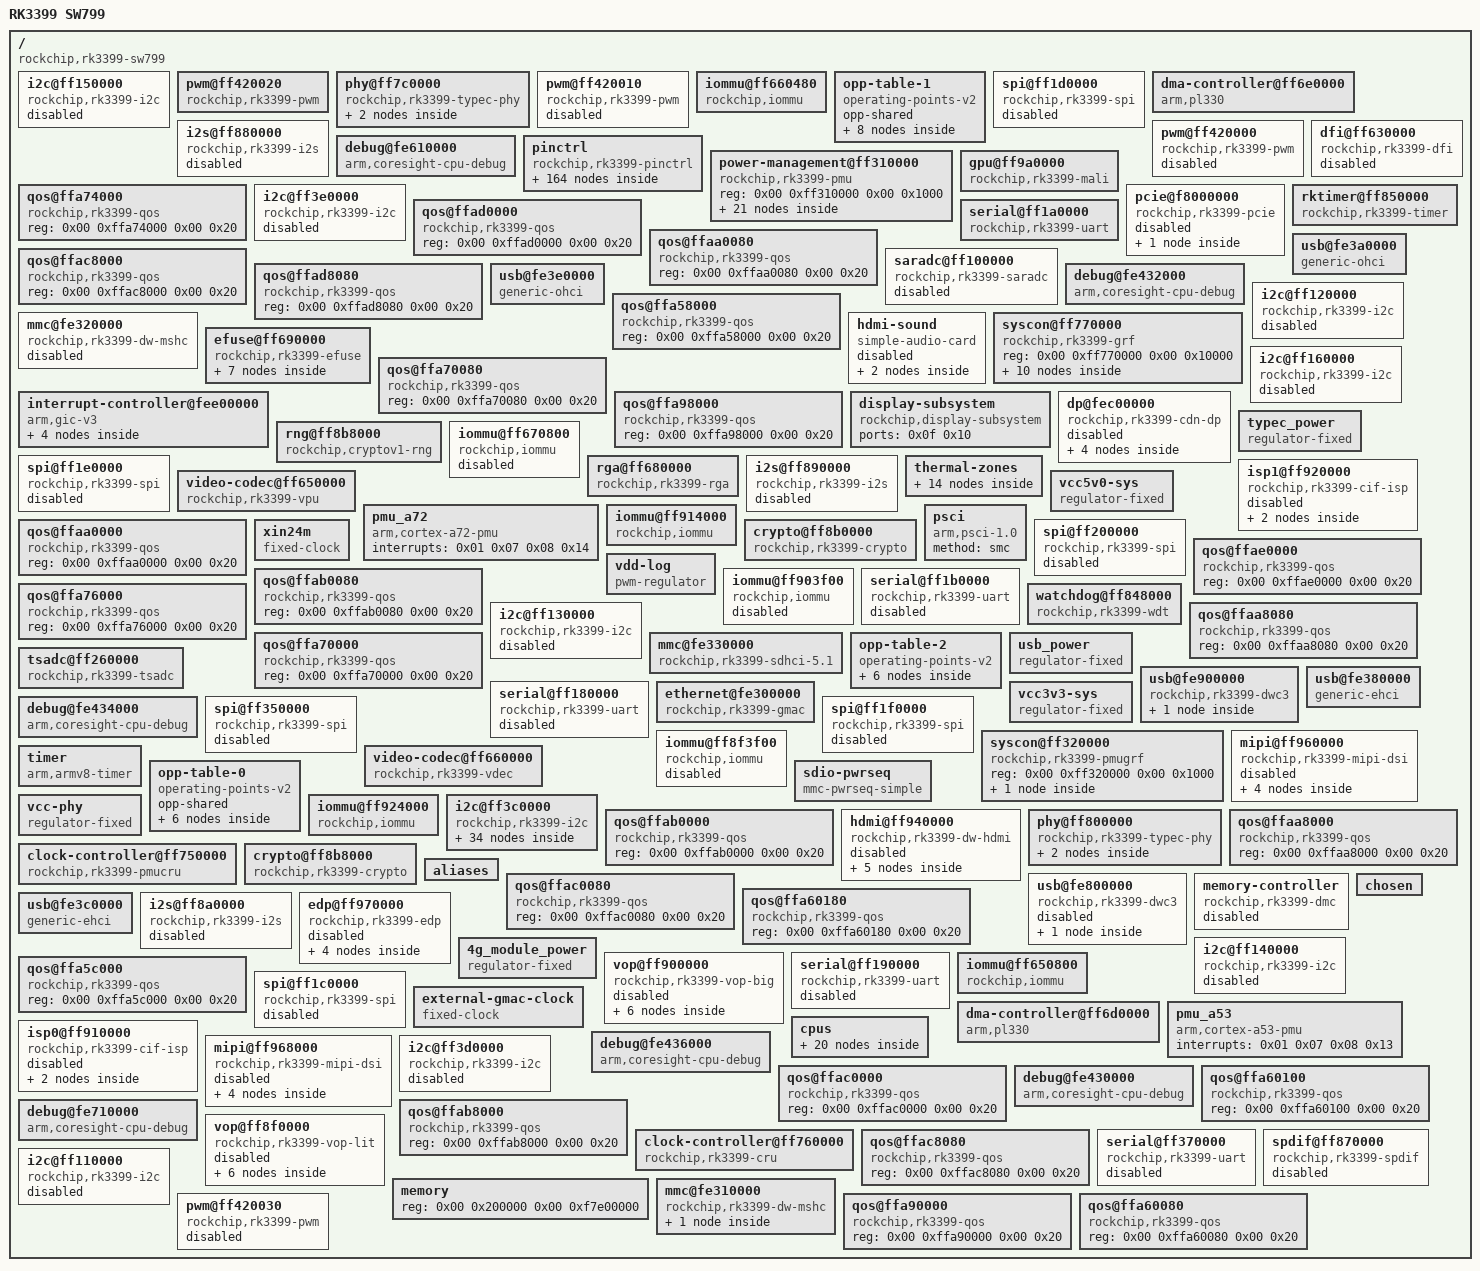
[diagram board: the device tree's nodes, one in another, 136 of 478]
/dts-v1/;

/ {
	#address-cells = <0x02>;
	model = "RK3399 SW799";
	serial-number = "8e98f8455ed5334b";
	#size-cells = <0x02>;
	interrupt-parent = <0x01>;
	compatible = "rockchip,rk3399-sw799", "rockchip,rk3399";

	i2c@ff150000 {
		pinctrl-names = "default";
		#address-cells = <0x01>;
		pinctrl-0 = <0x34>;
		clock-names = "i2c", "pclk";
		assigned-clocks = <0x08 0x45>;
		assigned-clock-rates = <0xbebc200>;
		interrupts = <0x00 0x25 0x04 0x00>;
		clocks = <0x08 0x45 0x08 0x159>;
		#size-cells = <0x00>;
		compatible = "rockchip,rk3399-i2c";
		status = "disabled";
		reg = <0x00 0xff150000 0x00 0x1000>;
		phandle = <0xc0>;
	};

	pwm@ff420020 {
		pinctrl-names = "default";
		pinctrl-0 = <0x7b>;
		clocks = <0x6c 0x1e>;
		#pwm-cells = <0x03>;
		compatible = "rockchip,rk3399-pwm", "rockchip,rk3288-pwm";
		status = "okay";
		reg = <0x00 0xff420020 0x00 0x10>;
		phandle = <0xa7>;
	};

	phy@ff7c0000 {
		power-domains = <0x18 0x08>;
		clock-names = "tcpdcore", "tcpdphy-ref";
		assigned-clocks = <0x08 0x7e>;
		assigned-clock-rates = <0x2faf080>;
		resets = <0x08 0x95 0x08 0x94 0x08 0x14c>;
		clocks = <0x08 0x7e 0x08 0x7d>;
		compatible = "rockchip,rk3399-typec-phy";
		status = "okay";
		rockchip,grf = <0x19>;
		reg = <0x00 0xff7c0000 0x00 0x40000>;
		phandle = <0xf7>;
		reset-names = "uphy", "uphy-pipe", "uphy-tcphy";

		dp-port {
			#phy-cells = <0x00>;
			phandle = <0x2c>;
		};

		usb3-port {
			#phy-cells = <0x00>;
			phandle = <0x29>;
		};
	};

	pwm@ff420010 {
		pinctrl-names = "default";
		pinctrl-0 = <0x7a>;
		clocks = <0x6c 0x1e>;
		#pwm-cells = <0x03>;
		compatible = "rockchip,rk3399-pwm", "rockchip,rk3288-pwm";
		status = "disabled";
		reg = <0x00 0xff420010 0x00 0x10>;
		phandle = <0xe8>;
	};

	iommu@ff660480 {
		power-domains = <0x18 0x20>;
		clock-names = "aclk", "iface";
		interrupts = <0x00 0x75 0x04 0x00>;
		clocks = <0x08 0xed 0x08 0x1ec>;
		#iommu-cells = <0x00>;
		compatible = "rockchip,iommu";
		reg = <0x00 0xff660480 0x00 0x40 0x00 0xff6604c0 0x00 0x40>;
		phandle = <0x7e>;
	};

	opp-table-1 {
		opp-shared;
		compatible = "operating-points-v2";
		phandle = <0x0d>;

		opp04 {
			opp-microvolt = <0xe7ef0 0xe7ef0 0x1312d0>;
			opp-hz = <0x00 0x47868c00>;
		};

		opp02 {
			opp-microvolt = <0xc96a8 0xc96a8 0x1312d0>;
			opp-hz = <0x00 0x30a32c00>;
		};

		opp00 {
			opp-microvolt = <0xc96a8 0xc96a8 0x1312d0>;
			opp-hz = <0x00 0x18519600>;
			clock-latency-ns = <0x9c40>;
		};

		opp07 {
			opp-microvolt = <0x124f80 0x124f80 0x1312d0>;
			opp-hz = <0x00 0x6b49d200>;
		};

		opp05 {
			opp-microvolt = <0xfa3e8 0xfa3e8 0x1312d0>;
			opp-hz = <0x00 0x54667200>;
		};

		opp03 {
			opp-microvolt = <0xd59f8 0xd59f8 0x1312d0>;
			opp-hz = <0x00 0x3c14dc00>;
		};

		opp01 {
			opp-microvolt = <0xc96a8 0xc96a8 0x1312d0>;
			opp-hz = <0x00 0x23c34600>;
		};

		opp06 {
			opp-microvolt = <0x10c8e0 0x10c8e0 0x1312d0>;
			opp-hz = <0x00 0x5fd82200>;
		};
	};

	spi@ff1d0000 {
		pinctrl-names = "default";
		#address-cells = <0x01>;
		pinctrl-0 = <0x3f 0x40 0x41 0x42>;
		clock-names = "spiclk", "apb_pclk";
		interrupts = <0x00 0x35 0x04 0x00>;
		clocks = <0x08 0x48 0x08 0x15c>;
		#size-cells = <0x00>;
		dma-names = "tx", "rx";
		compatible = "rockchip,rk3399-spi", "rockchip,rk3066-spi";
		status = "disabled";
		reg = <0x00 0xff1d0000 0x00 0x1000>;
		phandle = <0xc7>;
		dmas = <0x3a 0x0c 0x3a 0x0d>;
	};

	dma-controller@ff6e0000 {
		clock-names = "apb_pclk";
		interrupts = <0x00 0x07 0x04 0x00 0x00 0x08 0x04 0x00>;
		clocks = <0x08 0xd4>;
		arm,pl330-periph-burst;
		compatible = "arm,pl330", "arm,primecell";
		reg = <0x00 0xff6e0000 0x00 0x4000>;
		phandle = <0x3a>;
		#dma-cells = <0x01>;
	};

	i2s@ff880000 {
		power-domains = <0x18 0x1c>;
		pinctrl-names = "bclk_on", "bclk_off";
		pinctrl-0 = <0x82>;
		clock-names = "i2s_clk", "i2s_hclk";
		interrupts = <0x00 0x27 0x04 0x00>;
		clocks = <0x08 0x56 0x08 0x1d4>;
		dma-names = "tx", "rx";
		#sound-dai-cells = <0x00>;
		compatible = "rockchip,rk3399-i2s", "rockchip,rk3066-i2s";
		pinctrl-1 = <0x83>;
		status = "disabled";
		rockchip,grf = <0x19>;
		reg = <0x00 0xff880000 0x00 0x1000>;
		phandle = <0xfb>;
		dmas = <0x4b 0x00 0x4b 0x01>;
	};

	pwm@ff420000 {
		pinctrl-names = "default";
		pinctrl-0 = <0x79>;
		clocks = <0x6c 0x1e>;
		#pwm-cells = <0x03>;
		compatible = "rockchip,rk3399-pwm", "rockchip,rk3288-pwm";
		status = "disabled";
		reg = <0x00 0xff420000 0x00 0x10>;
		phandle = <0xe7>;
	};

	debug@fe610000 {
		clock-names = "apb_pclk";
		clocks = <0x08 0x14c>;
		cpu = <0x06>;
		compatible = "arm,coresight-cpu-debug", "arm,primecell";
		reg = <0x00 0xfe610000 0x00 0x1000>;
	};

	pinctrl {
		#address-cells = <0x02>;
		#size-cells = <0x02>;
		compatible = "rockchip,rk3399-pinctrl";
		rockchip,pmu = <0x11>;
		ranges;
		rockchip,grf = <0x19>;
		phandle = <0x10a>;

		i2c3 {

			i2c3-xfer {
				rockchip,pins = <0x04 0x11 0x01 0xa2 0x04 0x10 0x01 0xa2>;
				phandle = <0x32>;
			};
		};

		clock {

			clk-32k {
				rockchip,pins = <0x00 0x00 0x02 0xa2>;
				phandle = <0x11c>;
			};
		};

		spi2 {

			spi2-clk {
				rockchip,pins = <0x02 0x0b 0x01 0xa5>;
				phandle = <0x43>;
			};

			spi2-cs0 {
				rockchip,pins = <0x02 0x0c 0x01 0xa5>;
				phandle = <0x46>;
			};

			spi2-tx {
				rockchip,pins = <0x02 0x0a 0x01 0xa5>;
				phandle = <0x44>;
			};

			spi2-rx {
				rockchip,pins = <0x02 0x09 0x01 0xa5>;
				phandle = <0x45>;
			};
		};

		pcfg-pull-none-12ma {
			drive-strength = <0x0c>;
			bias-disable;
			phandle = <0xa4>;
		};

		pcfg-pull-up-20ma {
			drive-strength = <0x14>;
			phandle = <0x111>;
			bias-pull-up;
		};

		gpio@ff720000 {
			gpio-controller;
			interrupts = <0x00 0x0e 0x04 0x00>;
			clocks = <0x6c 0x17>;
			compatible = "rockchip,gpio-bank";
			#interrupt-cells = <0x02>;
			reg = <0x00 0xff720000 0x00 0x100>;
			phandle = <0x22>;
			#gpio-cells = <0x02>;
			interrupt-controller;
		};

		pcfg-input-pull-up {
			phandle = <0x11a>;
			bias-pull-up;
			input-enable;
		};

		i2s1 {

			i2s1-2ch-bus-bclk-off {
				rockchip,pins = <0x04 0x03 0x00 0xa2 0x04 0x04 0x01 0xa2 0x04 0x05 0x01 0xa2 0x04 0x06 0x01 0xa2 0x04 0x07 0x01 0xa2>;
				phandle = <0x122>;
			};

			i2s1-2ch-bus {
				rockchip,pins = <0x04 0x03 0x01 0xa2 0x04 0x04 0x01 0xa2 0x04 0x05 0x01 0xa2 0x04 0x06 0x01 0xa2 0x04 0x07 0x01 0xa2>;
				phandle = <0x84>;
			};
		};

		i2c1 {

			i2c1-xfer {
				rockchip,pins = <0x04 0x02 0x01 0xa2 0x04 0x01 0x01 0xa2>;
				phandle = <0x30>;
			};
		};

		gmac {

			rmii-pins {
				rockchip,pins = <0x03 0x0d 0x01 0xa2 0x03 0x0c 0x01 0xa3 0x03 0x0b 0x01 0xa2 0x03 0x0a 0x01 0xa2 0x03 0x09 0x01 0xa2 0x03 0x08 0x01 0xa2 0x03 0x07 0x01 0xa2 0x03 0x06 0x01 0xa2 0x03 0x05 0x01 0xa3 0x03 0x04 0x01 0xa3>;
				phandle = <0x11f>;
			};

			rgmii-pins {
				rockchip,pins = <0x03 0x11 0x01 0xa3 0x03 0x0e 0x01 0xa2 0x03 0x0d 0x01 0xa2 0x03 0x0c 0x01 0xa3 0x03 0x0b 0x01 0xa2 0x03 0x09 0x01 0xa2 0x03 0x08 0x01 0xa2 0x03 0x07 0x01 0xa2 0x03 0x06 0x01 0xa2 0x03 0x05 0x01 0xa3 0x03 0x04 0x01 0xa3 0x03 0x03 0x01 0xa2 0x03 0x02 0x01 0xa2 0x03 0x01 0x01 0xa3 0x03 0x00 0x01 0xa3>;
				phandle = <0x1d>;
			};
		};

		spi0 {

			spi0-tx {
				rockchip,pins = <0x03 0x05 0x02 0xa5>;
				phandle = <0x3c>;
			};

			spi0-rx {
				rockchip,pins = <0x03 0x04 0x02 0xa5>;
				phandle = <0x3d>;
			};

			spi0-cs1 {
				rockchip,pins = <0x03 0x08 0x02 0xa5>;
				phandle = <0x132>;
			};

			spi0-clk {
				rockchip,pins = <0x03 0x06 0x02 0xa5>;
				phandle = <0x3b>;
			};

			spi0-cs0 {
				rockchip,pins = <0x03 0x07 0x02 0xa5>;
				phandle = <0x3e>;
			};
		};

		pcfg-pull-down-4ma {
			drive-strength = <0x04>;
			bias-pull-down;
			phandle = <0x112>;
		};

		pcfg-pull-down {
			bias-pull-down;
			phandle = <0xa6>;
		};

		uart4 {

			uart4-xfer {
				rockchip,pins = <0x01 0x07 0x01 0xa5 0x01 0x08 0x01 0xa2>;
				phandle = <0x71>;
			};
		};

		pcfg-pull-none-18ma {
			drive-strength = <0x12>;
			bias-disable;
			phandle = <0x10c>;
		};

		i2c8 {

			i2c8-xfer {
				rockchip,pins = <0x01 0x15 0x01 0xa2 0x01 0x14 0x01 0xa2>;
				phandle = <0x78>;
			};
		};

		pcfg-input-pull-down {
			bias-pull-down;
			phandle = <0x11b>;
			input-enable;
		};

		pcfg-pull-none-20ma {
			drive-strength = <0x14>;
			bias-disable;
			phandle = <0x10d>;
		};

		gpio@ff730000 {
			gpio-controller;
			interrupts = <0x00 0x0f 0x04 0x00>;
			clocks = <0x6c 0x18>;
			compatible = "rockchip,gpio-bank";
			#interrupt-cells = <0x02>;
			reg = <0x00 0xff730000 0x00 0x100>;
			phandle = <0x74>;
			#gpio-cells = <0x02>;
			interrupt-controller;
		};

		i2c6 {

			i2c6-xfer {
				rockchip,pins = <0x02 0x0a 0x02 0xa2 0x02 0x09 0x02 0xa2>;
				phandle = <0x34>;
			};
		};

		uarthdcp {

			uarthdcp-xfer {
				rockchip,pins = <0x04 0x15 0x02 0xa5 0x04 0x16 0x02 0xa2>;
				phandle = <0x13c>;
			};
		};

		pwm1 {

			pwm1-pin {
				rockchip,pins = <0x04 0x16 0x01 0xa2>;
				phandle = <0x7a>;
			};

			pwm1-pin-pull-down {
				rockchip,pins = <0x04 0x16 0x01 0xa6>;
				phandle = <0x140>;
			};
		};

		uart2b {

			uart2b-xfer {
				rockchip,pins = <0x04 0x10 0x02 0xa5 0x04 0x11 0x02 0xa2>;
				phandle = <0x139>;
			};
		};

		edp {

			edp-hpd {
				rockchip,pins = <0x04 0x17 0x02 0xa2>;
				phandle = <0x9d>;
			};
		};

		spi5 {

			spi5-cs0 {
				rockchip,pins = <0x02 0x17 0x02 0xa5>;
				phandle = <0x4f>;
			};

			spi5-tx {
				rockchip,pins = <0x02 0x15 0x02 0xa5>;
				phandle = <0x4d>;
			};

			spi5-rx {
				rockchip,pins = <0x02 0x14 0x02 0xa5>;
				phandle = <0x4e>;
			};

			spi5-clk {
				rockchip,pins = <0x02 0x16 0x02 0xa5>;
				phandle = <0x4c>;
			};
		};

		tsadc {

			otp-pin {
				rockchip,pins = <0x01 0x06 0x00 0xa2>;
				phandle = <0x55>;
			};

			otp-out {
				rockchip,pins = <0x01 0x06 0x01 0xa2>;
				phandle = <0x56>;
			};
		};

		uart0 {

			uart0-cts {
				rockchip,pins = <0x02 0x12 0x01 0xa2>;
				phandle = <0x136>;
			};

			uart0-rts {
				rockchip,pins = <0x02 0x13 0x01 0xa2>;
				phandle = <0x137>;
			};

			uart0-xfer {
				rockchip,pins = <0x02 0x10 0x01 0xa5 0x02 0x11 0x01 0xa2>;
				phandle = <0x36>;
			};
		};

		i2c4 {

			i2c4-xfer {
				rockchip,pins = <0x01 0x0c 0x01 0xa2 0x01 0x0b 0x01 0xa2>;
				phandle = <0x77>;
			};
		};

		pcfg-pull-down-12ma {
			drive-strength = <0x0c>;
			bias-pull-down;
			phandle = <0x114>;
		};

		spdif {

			spdif-bus-1 {
				rockchip,pins = <0x03 0x10 0x03 0xa2>;
				phandle = <0x131>;
			};

			spdif-bus {
				rockchip,pins = <0x04 0x15 0x01 0xa2>;
				phandle = <0x81>;
			};
		};

		pcfg-output-high {
			output-high;
			phandle = <0x117>;
		};

		pcie {

			pci-clkreqn-cpm {
				rockchip,pins = <0x02 0x1a 0x00 0xa2>;
				phandle = <0x145>;
			};

			pci-clkreqnb-cpm {
				rockchip,pins = <0x04 0x18 0x00 0xa2>;
				phandle = <0x146>;
			};
		};

		pcfg-pull-up {
			phandle = <0xa5>;
			bias-pull-up;
		};

		spi3 {

			spi3-tx {
				rockchip,pins = <0x01 0x10 0x01 0xa5>;
				phandle = <0x6e>;
			};

			spi3-rx {
				rockchip,pins = <0x01 0x0f 0x01 0xa5>;
				phandle = <0x6f>;
			};

			spi3-clk {
				rockchip,pins = <0x01 0x11 0x01 0xa5>;
				phandle = <0x6d>;
			};

			spi3-cs0 {
				rockchip,pins = <0x01 0x12 0x01 0xa5>;
				phandle = <0x70>;
			};
		};

		pwm3a {

			pwm3a-pin {
				rockchip,pins = <0x00 0x06 0x01 0xa2>;
				phandle = <0x7c>;
			};
		};

		sdio0 {

			sdio0-clk {
				rockchip,pins = <0x02 0x19 0x01 0xa2>;
				phandle = <0x21>;
			};

			sdio0-wp {
				rockchip,pins = <0x00 0x03 0x01 0xa5>;
				phandle = <0x127>;
			};

			sdio0-bus4 {
				rockchip,pins = <0x02 0x14 0x01 0xa5 0x02 0x15 0x01 0xa5 0x02 0x16 0x01 0xa5 0x02 0x17 0x01 0xa5>;
				phandle = <0x1f>;
			};

			sdio0-bkpwr {
				rockchip,pins = <0x02 0x1c 0x01 0xa5>;
				phandle = <0x126>;
			};

			sdio0-cd {
				rockchip,pins = <0x02 0x1a 0x01 0xa5>;
				phandle = <0x124>;
			};

			sdio0-pwr {
				rockchip,pins = <0x02 0x1b 0x01 0xa5>;
				phandle = <0x125>;
			};

			sdio0-int {
				rockchip,pins = <0x00 0x04 0x01 0xa5>;
				phandle = <0x128>;
			};

			sdio0-bus1 {
				rockchip,pins = <0x02 0x14 0x01 0xa5>;
				phandle = <0x123>;
			};

			sdio0-cmd {
				rockchip,pins = <0x02 0x18 0x01 0xa5>;
				phandle = <0x20>;
			};
		};

		pcfg-pull-up-2ma {
			drive-strength = <0x02>;
			phandle = <0x10e>;
			bias-pull-up;
		};

		i2c2 {

			i2c2-xfer {
				rockchip,pins = <0x02 0x01 0x02 0xa4 0x02 0x00 0x02 0xa4>;
				phandle = <0x31>;
			};
		};

		pcfg-input-enable {
			phandle = <0x119>;
			input-enable;
		};

		pcfg-pull-none {
			bias-disable;
			phandle = <0xa2>;
		};

		spi1 {

			spi1-cs0 {
				rockchip,pins = <0x01 0x0a 0x02 0xa5>;
				phandle = <0x42>;
			};

			spi1-clk {
				rockchip,pins = <0x01 0x09 0x02 0xa5>;
				phandle = <0x3f>;
			};

			spi1-tx {
				rockchip,pins = <0x01 0x08 0x02 0xa5>;
				phandle = <0x40>;
			};

			spi1-rx {
				rockchip,pins = <0x01 0x07 0x02 0xa5>;
				phandle = <0x41>;
			};
		};

		gpio@ff780000 {
			gpio-controller;
			interrupts = <0x00 0x10 0x04 0x00>;
			clocks = <0x08 0x150>;
			compatible = "rockchip,gpio-bank";
			#interrupt-cells = <0x02>;
			reg = <0x00 0xff780000 0x00 0x100>;
			phandle = <0xa9>;
			#gpio-cells = <0x02>;
			interrupt-controller;
		};

		pcfg-pull-down-18ma {
			drive-strength = <0x12>;
			bias-pull-down;
			phandle = <0x115>;
		};

		sdmmc {

			sdmmc-wp {
				rockchip,pins = <0x00 0x08 0x01 0xa5>;
				phandle = <0x12e>;
			};

			sdmmc-bus1 {
				rockchip,pins = <0x04 0x08 0x01 0xa5>;
				phandle = <0x129>;
			};

			sdmmc-cd {
				rockchip,pins = <0x00 0x07 0x01 0xa5>;
				phandle = <0x12d>;
			};

			sdmmc-bus4 {
				rockchip,pins = <0x04 0x08 0x01 0xa5 0x04 0x09 0x01 0xa5 0x04 0x0a 0x01 0xa5 0x04 0x0b 0x01 0xa5>;
				phandle = <0x12a>;
			};

			sdmmc-cmd {
				rockchip,pins = <0x04 0x0d 0x01 0xa5>;
				phandle = <0x12c>;
			};

			sdmmc-clk {
				rockchip,pins = <0x04 0x0c 0x01 0xa2>;
				phandle = <0x12b>;
			};
		};

		i2s0 {

			i2s0-8ch-bus {
				rockchip,pins = <0x03 0x18 0x01 0xa2 0x03 0x19 0x01 0xa2 0x03 0x1a 0x01 0xa2 0x03 0x1b 0x01 0xa2 0x03 0x1c 0x01 0xa2 0x03 0x1d 0x01 0xa2 0x03 0x1e 0x01 0xa2 0x03 0x1f 0x01 0xa2 0x04 0x00 0x01 0xa2>;
				phandle = <0x82>;
			};

			i2s0-8ch-bus-bclk-off {
				rockchip,pins = <0x03 0x18 0x00 0xa2 0x03 0x19 0x01 0xa2 0x03 0x1a 0x01 0xa2 0x03 0x1b 0x01 0xa2 0x03 0x1c 0x01 0xa2 0x03 0x1d 0x01 0xa2 0x03 0x1e 0x01 0xa2 0x03 0x1f 0x01 0xa2 0x04 0x00 0x01 0xa2>;
				phandle = <0x83>;
			};

			i2s0-2ch-bus-bclk-off {
				rockchip,pins = <0x03 0x18 0x00 0xa2 0x03 0x19 0x01 0xa2 0x03 0x1a 0x01 0xa2 0x03 0x1b 0x01 0xa2 0x03 0x1f 0x01 0xa2 0x04 0x00 0x01 0xa2>;
				phandle = <0x121>;
			};

			i2s0-2ch-bus {
				rockchip,pins = <0x03 0x18 0x01 0xa2 0x03 0x19 0x01 0xa2 0x03 0x1a 0x01 0xa2 0x03 0x1b 0x01 0xa2 0x03 0x1f 0x01 0xa2 0x04 0x00 0x01 0xa2>;
				phandle = <0x120>;
			};
		};

		i2c0 {

			i2c0-xfer {
				rockchip,pins = <0x01 0x0f 0x02 0xa2 0x01 0x10 0x02 0xa2>;
				phandle = <0x72>;
			};
		};

		suspend {

			ap-pwroff {
				rockchip,pins = <0x01 0x05 0x01 0xa2>;
				phandle = <0x12f>;
			};

			ddrio-pwroff {
				rockchip,pins = <0x00 0x01 0x01 0xa2>;
				phandle = <0x130>;
			};
		};

		testclk {

			test-clkout2 {
				rockchip,pins = <0x00 0x08 0x03 0xa2>;
				phandle = <0x135>;
			};

			test-clkout0 {
				rockchip,pins = <0x00 0x00 0x01 0xa2>;
				phandle = <0x133>;
			};

			test-clkout1 {
				rockchip,pins = <0x02 0x19 0x02 0xa2>;
				phandle = <0x134>;
			};
		};

		pcfg-pull-up-8ma {
			drive-strength = <0x08>;
			phandle = <0x10f>;
			bias-pull-up;
		};

		pcfg-pull-down-20ma {
			drive-strength = <0x14>;
			bias-pull-down;
			phandle = <0x116>;
		};

		pcfg-pull-none-13ma {
			drive-strength = <0x0d>;
			bias-disable;
			phandle = <0xa3>;
		};

		uart3 {

			uart3-cts {
				rockchip,pins = <0x03 0x10 0x02 0xa2>;
				phandle = <0x13a>;
			};

			uart3-rts {
				rockchip,pins = <0x03 0x11 0x02 0xa2>;
				phandle = <0x13b>;
			};

			uart3-xfer {
				rockchip,pins = <0x03 0x0e 0x02 0xa5 0x03 0x0f 0x02 0xa2>;
				phandle = <0x39>;
			};
		};

		pcfg-output-low {
			phandle = <0x118>;
			output-low;
		};

		i2c7 {

			i2c7-xfer {
				rockchip,pins = <0x02 0x08 0x02 0xa2 0x02 0x07 0x02 0xa2>;
				phandle = <0x35>;
			};
		};

		pwm2 {

			pwm2-pin {
				rockchip,pins = <0x01 0x13 0x01 0xa2>;
				phandle = <0x7b>;
			};

			pwm2-pin-pull-down {
				rockchip,pins = <0x01 0x13 0x01 0xa6>;
				phandle = <0x141>;
			};
		};

		uart2c {

			uart2c-xfer {
				rockchip,pins = <0x04 0x13 0x01 0xa5 0x04 0x14 0x01 0xa2>;
				phandle = <0x38>;
			};
		};

		uart1 {

			uart1-xfer {
				rockchip,pins = <0x03 0x0c 0x02 0xa5 0x03 0x0d 0x02 0xa2>;
				phandle = <0x37>;
			};
		};

		hdmi {

			hdmi-i2c-xfer {
				rockchip,pins = <0x04 0x11 0x03 0xa2 0x04 0x10 0x03 0xa2>;
				phandle = <0x143>;
			};

			hdmi-cec {
				rockchip,pins = <0x04 0x17 0x01 0xa2>;
				phandle = <0x144>;
			};
		};

		gpio@ff790000 {
			gpio-controller;
			interrupts = <0x00 0x12 0x04 0x00>;
			clocks = <0x08 0x152>;
			compatible = "rockchip,gpio-bank";
			#interrupt-cells = <0x02>;
			reg = <0x00 0xff790000 0x00 0x100>;
			phandle = <0x10b>;
			#gpio-cells = <0x02>;
			interrupt-controller;
		};

		i2c5 {

			i2c5-xfer {
				rockchip,pins = <0x03 0x0b 0x02 0xa2 0x03 0x0a 0x02 0xa2>;
				phandle = <0x33>;
			};
		};

		gpio@ff788000 {
			gpio-controller;
			interrupts = <0x00 0x11 0x04 0x00>;
			clocks = <0x08 0x151>;
			compatible = "rockchip,gpio-bank";
			#interrupt-cells = <0x02>;
			reg = <0x00 0xff788000 0x00 0x100>;
			phandle = <0x1b>;
			#gpio-cells = <0x02>;
			interrupt-controller;
		};

		pwm0 {

			pwm0-pin-pull-down {
				rockchip,pins = <0x04 0x12 0x01 0xa6>;
				phandle = <0x13d>;
			};

			vop1-pwm-pin {
				rockchip,pins = <0x04 0x12 0x03 0xa2>;
				phandle = <0x13f>;
			};

			vop0-pwm-pin {
				rockchip,pins = <0x04 0x12 0x02 0xa2>;
				phandle = <0x13e>;
			};

			pwm0-pin {
				rockchip,pins = <0x04 0x12 0x01 0xa2>;
				phandle = <0x79>;
			};
		};

		cif {

			cif-clkin {
				rockchip,pins = <0x02 0x0a 0x03 0xa2>;
				phandle = <0x11d>;
			};

			cif-clkouta {
				rockchip,pins = <0x02 0x0b 0x03 0xa2>;
				phandle = <0x11e>;
			};
		};

		uart2a {

			uart2a-xfer {
				rockchip,pins = <0x04 0x08 0x02 0xa5 0x04 0x09 0x02 0xa2>;
				phandle = <0x138>;
			};
		};

		spi4 {

			spi4-clk {
				rockchip,pins = <0x03 0x02 0x02 0xa5>;
				phandle = <0x47>;
			};

			spi4-tx {
				rockchip,pins = <0x03 0x01 0x02 0xa5>;
				phandle = <0x48>;
			};

			spi4-rx {
				rockchip,pins = <0x03 0x00 0x02 0xa5>;
				phandle = <0x49>;
			};

			spi4-cs0 {
				rockchip,pins = <0x03 0x03 0x02 0xa5>;
				phandle = <0x4a>;
			};
		};

		pcfg-pull-down-8ma {
			drive-strength = <0x08>;
			bias-pull-down;
			phandle = <0x113>;
		};

		pwm3b {

			pwm3b-pin {
				rockchip,pins = <0x01 0x0e 0x01 0xa2>;
				phandle = <0x142>;
			};
		};

		pcfg-pull-up-18ma {
			drive-strength = <0x12>;
			phandle = <0x110>;
			bias-pull-up;
		};
	};

	power-management@ff310000 {
		compatible = "rockchip,rk3399-pmu", "syscon", "simple-mfd";
		reg = <0x00 0xff310000 0x00 0x1000>;
		phandle = <0xd4>;

		power-controller {
			#address-cells = <0x01>;
			#size-cells = <0x00>;
			#power-domain-cells = <0x01>;
			compatible = "rockchip,rk3399-power-controller";
			phandle = <0x18>;

			power-domain@9 {
				clocks = <0x08 0x80 0x08 0x7f>;
				#power-domain-cells = <0x00>;
				reg = <0x09>;
			};

			power-domain@27 {
				clocks = <0x08 0x1ce 0x08 0x4c>;
				#power-domain-cells = <0x00>;
				reg = <0x1b>;
				pm_qos = <0x60>;
			};

			power-domain@35 {
				clocks = <0x08 0xd0>;
				#power-domain-cells = <0x00>;
				reg = <0x23>;
				pm_qos = <0x5d>;
			};

			power-domain@25 {
				clocks = <0x08 0x16c>;
				#power-domain-cells = <0x00>;
				reg = <0x19>;
			};

			power-domain@15 {
				#address-cells = <0x01>;
				#size-cells = <0x00>;
				#power-domain-cells = <0x01>;
				reg = <0x0f>;

				power-domain@19 {
					clocks = <0x08 0xe5 0x08 0x1df>;
					#power-domain-cells = <0x00>;
					reg = <0x13>;
					pm_qos = <0x65 0x66>;
				};

				power-domain@21 {
					clocks = <0x08 0xde 0x08 0x1e7 0x08 0x172>;
					#power-domain-cells = <0x00>;
					reg = <0x15>;
					pm_qos = <0x64>;
				};

				power-domain@16 {
					#address-cells = <0x01>;
					#size-cells = <0x00>;
					#power-domain-cells = <0x01>;
					reg = <0x10>;

					power-domain@17 {
						clocks = <0x08 0xd9 0x08 0x1d9>;
						#power-domain-cells = <0x00>;
						reg = <0x11>;
						pm_qos = <0x69 0x6a>;
					};

					power-domain@18 {
						clocks = <0x08 0xdb 0x08 0x1db>;
						#power-domain-cells = <0x00>;
						reg = <0x12>;
						pm_qos = <0x6b>;
					};
				};

				power-domain@20 {
					clocks = <0x08 0xe6 0x08 0x1e0>;
					#power-domain-cells = <0x00>;
					reg = <0x14>;
					pm_qos = <0x67 0x68>;
				};
			};

			power-domain@33 {
				clocks = <0x08 0xdc 0x08 0x1e5>;
				#power-domain-cells = <0x00>;
				reg = <0x21>;
				pm_qos = <0x58 0x59>;
			};

			power-domain@23 {
				clocks = <0x08 0xf0>;
				#power-domain-cells = <0x00>;
				reg = <0x17>;
				pm_qos = <0x5e>;
			};

			power-domain@31 {
				clocks = <0x08 0xeb 0x08 0x1ea>;
				#power-domain-cells = <0x00>;
				reg = <0x1f>;
				pm_qos = <0x5a>;
			};

			power-domain@28 {
				clocks = <0x08 0x1ee>;
				#power-domain-cells = <0x00>;
				reg = <0x1c>;
				pm_qos = <0x61>;
			};

			power-domain@8 {
				clocks = <0x08 0x7e 0x08 0x7d>;
				#power-domain-cells = <0x00>;
				reg = <0x08>;
			};

			power-domain@34 {
				clocks = <0x08 0xe1 0x08 0x1dd>;
				#power-domain-cells = <0x00>;
				reg = <0x22>;
				pm_qos = <0x57>;
			};

			power-domain@24 {
				clocks = <0x08 0xf4>;
				#power-domain-cells = <0x00>;
				reg = <0x18>;
				pm_qos = <0x62 0x63>;
			};

			power-domain@32 {
				clocks = <0x08 0xed 0x08 0x1ec 0x08 0x9f 0x08 0x9e>;
				#power-domain-cells = <0x00>;
				reg = <0x20>;
				pm_qos = <0x5b 0x5c>;
			};

			power-domain@22 {
				clocks = <0x08 0xd5 0x08 0x166>;
				#power-domain-cells = <0x00>;
				reg = <0x16>;
				pm_qos = <0x5f>;
			};
		};
	};

	qos@ffa74000 {
		compatible = "rockchip,rk3399-qos", "syscon";
		reg = <0x00 0xffa74000 0x00 0x20>;
		phandle = <0x60>;
	};

	gpu@ff9a0000 {
		power-domains = <0x18 0x23>;
		mali-supply = <0xa1>;
		interrupts = <0x00 0x14 0x04 0x00 0x00 0x15 0x04 0x00 0x00 0x13 0x04 0x00>;
		clocks = <0x08 0xd0>;
		compatible = "rockchip,rk3399-mali", "arm,mali-t860";
		status = "okay";
		interrupt-names = "job", "mmu", "gpu";
		reg = <0x00 0xff9a0000 0x00 0x10000>;
		phandle = <0x54>;
		operating-points-v2 = <0xa0>;
		#cooling-cells = <0x02>;
	};

	dfi@ff630000 {
		clock-names = "pclk_ddr_mon";
		interrupts = <0x00 0x83 0x04 0x00>;
		clocks = <0x08 0x179>;
		compatible = "rockchip,rk3399-dfi";
		rockchip,pmu = <0x11>;
		status = "disabled";
		reg = <0x00 0xff630000 0x00 0x4000>;
		phandle = <0x12>;
	};

	i2c@ff3e0000 {
		pinctrl-names = "default";
		#address-cells = <0x01>;
		pinctrl-0 = <0x78>;
		clock-names = "i2c", "pclk";
		assigned-clocks = <0x6c 0x0b>;
		assigned-clock-rates = <0xbebc200>;
		interrupts = <0x00 0x3a 0x04 0x00>;
		clocks = <0x6c 0x0b 0x6c 0x1d>;
		#size-cells = <0x00>;
		compatible = "rockchip,rk3399-i2c";
		status = "disabled";
		reg = <0x00 0xff3e0000 0x00 0x1000>;
		phandle = <0xe6>;
	};

	pcie@f8000000 {
		#address-cells = <0x03>;
		phy-names = "pcie-phy-0", "pcie-phy-1", "pcie-phy-2", "pcie-phy-3";
		bus-range = <0x00 0x1f>;
		clock-names = "aclk", "aclk-perf", "hclk", "pm";
		reg-names = "axi-base", "apb-base";
		resets = <0x08 0x82 0x08 0x83 0x08 0x84 0x08 0x85 0x08 0x86 0x08 0x81 0x08 0x80>;
		interrupts = <0x00 0x31 0x04 0x00 0x00 0x32 0x04 0x00 0x00 0x33 0x04 0x00>;
		clocks = <0x08 0xc5 0x08 0xc4 0x08 0x147 0x08 0xa0>;
		interrupt-map = <0x00 0x00 0x00 0x01 0x15 0x00 0x00 0x00 0x00 0x02 0x15 0x01 0x00 0x00 0x00 0x03 0x15 0x02 0x00 0x00 0x00 0x04 0x15 0x03>;
		#size-cells = <0x02>;
		aspm-no-l0s;
		max-link-speed = <0x01>;
		device_type = "pci";
		interrupt-map-mask = <0x00 0x00 0x00 0x07>;
		compatible = "rockchip,rk3399-pcie";
		ranges = <0x82000000 0x00 0xfa000000 0x00 0xfa000000 0x00 0x1e00000 0x81000000 0x00 0xfbe00000 0x00 0xfbe00000 0x00 0x100000>;
		msi-map = <0x00 0x16 0x00 0x1000>;
		#interrupt-cells = <0x01>;
		status = "disabled";
		interrupt-names = "sys", "legacy", "client";
		phys = <0x17 0x00 0x17 0x01 0x17 0x02 0x17 0x03>;
		reg = <0x00 0xf8000000 0x00 0x2000000 0x00 0xfd000000 0x00 0x1000000>;
		phandle = <0xab>;
		reset-names = "core", "mgmt", "mgmt-sticky", "pipe", "pm", "pclk", "aclk";

		interrupt-controller {
			#address-cells = <0x00>;
			#interrupt-cells = <0x01>;
			phandle = <0x15>;
			interrupt-controller;
		};
	};

	qos@ffad0000 {
		compatible = "rockchip,rk3399-qos", "syscon";
		reg = <0x00 0xffad0000 0x00 0x20>;
		phandle = <0x6b>;
	};

	rktimer@ff850000 {
		clock-names = "pclk", "timer";
		interrupts = <0x00 0x51 0x04 0x00>;
		clocks = <0x08 0x168 0x08 0x5a>;
		compatible = "rockchip,rk3399-timer";
		reg = <0x00 0xff850000 0x00 0x1000>;
		phandle = <0xf9>;
	};

	qos@ffaa0080 {
		compatible = "rockchip,rk3399-qos", "syscon";
		reg = <0x00 0xffaa0080 0x00 0x20>;
		phandle = <0x66>;
	};

	serial@ff1a0000 {
		reg-io-width = <0x04>;
		pinctrl-names = "default";
		pinctrl-0 = <0x38>;
		clock-names = "baudclk", "apb_pclk";
		interrupts = <0x00 0x64 0x04 0x00>;
		clocks = <0x08 0x53 0x08 0x162>;
		compatible = "rockchip,rk3399-uart", "snps,dw-apb-uart";
		status = "okay";
		reg = <0x00 0xff1a0000 0x00 0x100>;
		phandle = <0xc4>;
		reg-shift = <0x02>;
	};

	qos@ffac8000 {
		compatible = "rockchip,rk3399-qos", "syscon";
		reg = <0x00 0xffac8000 0x00 0x20>;
		phandle = <0x69>;
	};

	usb@fe3a0000 {
		phy-names = "usb";
		interrupts = <0x00 0x1c 0x04 0x00>;
		clocks = <0x08 0x1c8 0x08 0x1c9 0x24>;
		compatible = "generic-ohci";
		status = "okay";
		phys = <0x25>;
		reg = <0x00 0xfe3a0000 0x00 0x20000>;
		phandle = <0xb0>;
	};

	saradc@ff100000 {
		clock-names = "saradc", "apb_pclk";
		resets = <0x08 0xd4>;
		interrupts = <0x00 0x3e 0x04 0x00>;
		clocks = <0x08 0x50 0x08 0x165>;
		#io-channel-cells = <0x01>;
		compatible = "rockchip,rk3399-saradc";
		status = "disabled";
		reg = <0x00 0xff100000 0x00 0x100>;
		phandle = <0xb9>;
		reset-names = "saradc-apb";
	};

	qos@ffad8080 {
		compatible = "rockchip,rk3399-qos", "syscon";
		reg = <0x00 0xffad8080 0x00 0x20>;
		phandle = <0xd3>;
	};

	usb@fe3e0000 {
		phy-names = "usb";
		interrupts = <0x00 0x20 0x04 0x00>;
		clocks = <0x08 0x1ca 0x08 0x1cb 0x26>;
		compatible = "generic-ohci";
		status = "okay";
		phys = <0x27>;
		reg = <0x00 0xfe3e0000 0x00 0x20000>;
		phandle = <0xb2>;
	};

	debug@fe432000 {
		clock-names = "apb_pclk";
		clocks = <0x08 0x14d>;
		cpu = <0x03>;
		compatible = "arm,coresight-cpu-debug", "arm,primecell";
		reg = <0x00 0xfe432000 0x00 0x1000>;
	};

	i2c@ff120000 {
		pinctrl-names = "default";
		#address-cells = <0x01>;
		pinctrl-0 = <0x31>;
		clock-names = "i2c", "pclk";
		assigned-clocks = <0x08 0x42>;
		assigned-clock-rates = <0xbebc200>;
		interrupts = <0x00 0x23 0x04 0x00>;
		clocks = <0x08 0x42 0x08 0x156>;
		#size-cells = <0x00>;
		compatible = "rockchip,rk3399-i2c";
		status = "disabled";
		reg = <0x00 0xff120000 0x00 0x1000>;
		phandle = <0xbd>;
	};

	qos@ffa58000 {
		compatible = "rockchip,rk3399-qos", "syscon";
		reg = <0x00 0xffa58000 0x00 0x20>;
		phandle = <0x5e>;
	};

	mmc@fe320000 {
		power-domains = <0x18 0x1b>;
		fifo-depth = <0x100>;
		clock-names = "biu", "ciu", "ciu-drive", "ciu-sample";
		assigned-clocks = <0x08 0x1cd>;
		assigned-clock-rates = <0xbebc200>;
		resets = <0x08 0x7a>;
		interrupts = <0x00 0x41 0x04 0x00>;
		clocks = <0x08 0x1ce 0x08 0x4c 0x08 0x9a 0x08 0x9b>;
		compatible = "rockchip,rk3399-dw-mshc", "rockchip,rk3288-dw-mshc";
		status = "disabled";
		reg = <0x00 0xfe320000 0x00 0x4000>;
		phandle = <0xae>;
		max-frequency = <0x8f0d180>;
		reset-names = "reset";
	};

	hdmi-sound {
		simple-audio-card,name = "hdmi-sound";
		simple-audio-card,format = "i2s";
		compatible = "simple-audio-card";
		status = "disabled";
		phandle = <0x101>;
		simple-audio-card,mclk-fs = <0x100>;

		simple-audio-card,cpu {
			sound-dai = <0x95>;
		};

		simple-audio-card,codec {
			sound-dai = <0x96>;
		};
	};

	syscon@ff770000 {
		#address-cells = <0x01>;
		#size-cells = <0x01>;
		compatible = "rockchip,rk3399-grf", "syscon", "simple-mfd";
		reg = <0x00 0xff770000 0x00 0x10000>;
		phandle = <0x19>;

		mipi-dphy-rx0 {
			power-domains = <0x18 0x0f>;
			clock-names = "dphy-ref", "dphy-cfg", "grf";
			clocks = <0x08 0x77 0x08 0xa5 0x08 0x16f>;
			#phy-cells = <0x00>;
			compatible = "rockchip,rk3399-mipi-dphy-rx0";
			status = "disabled";
			phandle = <0x92>;
		};

		pcie-phy {
			clock-names = "refclk";
			resets = <0x08 0x87>;
			clocks = <0x08 0x8a>;
			#phy-cells = <0x01>;
			compatible = "rockchip,rk3399-pcie-phy";
			status = "disabled";
			phandle = <0x17>;
			reset-names = "phy";
		};

		usb2phy@e460 {
			clock-output-names = "clk_usbphy1_480m";
			clock-names = "phyclk";
			clocks = <0x08 0x7c>;
			#clock-cells = <0x00>;
			compatible = "rockchip,rk3399-usb2phy";
			status = "okay";
			reg = <0xe460 0x10>;
			phandle = <0x26>;

			host-port {
				interrupts = <0x00 0x1f 0x04 0x00>;
				#phy-cells = <0x00>;
				status = "okay";
				interrupt-names = "linestate";
				phandle = <0x27>;
			};

			otg-port {
				interrupts = <0x00 0x6c 0x04 0x00 0x00 0x6d 0x04 0x00 0x00 0x6f 0x04 0x00>;
				#phy-cells = <0x00>;
				status = "okay";
				interrupt-names = "otg-bvalid", "otg-id", "linestate";
				phandle = <0x2a>;
			};
		};

		usb2phy@e450 {
			clock-output-names = "clk_usbphy0_480m";
			clock-names = "phyclk";
			clocks = <0x08 0x7b>;
			#clock-cells = <0x00>;
			compatible = "rockchip,rk3399-usb2phy";
			status = "okay";
			reg = <0xe450 0x10>;
			phandle = <0x24>;

			host-port {
				interrupts = <0x00 0x1b 0x04 0x00>;
				#phy-cells = <0x00>;
				status = "okay";
				interrupt-names = "linestate";
				phandle = <0x25>;
			};

			otg-port {
				interrupts = <0x00 0x67 0x04 0x00 0x00 0x68 0x04 0x00 0x00 0x6a 0x04 0x00>;
				#phy-cells = <0x00>;
				status = "disable";
				interrupt-names = "otg-bvalid", "otg-id", "linestate";
				phandle = <0x28>;
			};
		};

		io-domains {
			compatible = "rockchip,rk3399-io-voltage-domain";
			status = "disabled";
			phandle = <0xf6>;
		};

		phy@f780 {
			clock-names = "emmcclk";
			clocks = <0x80>;
			drive-impedance-ohm = <0x32>;
			#phy-cells = <0x00>;
			compatible = "rockchip,rk3399-emmc-phy";
			status = "okay";
			reg = <0xf780 0x24>;
			phandle = <0x23>;
		};
	};

	efuse@ff690000 {
		#address-cells = <0x01>;
		clock-names = "pclk_efuse";
		clocks = <0x08 0x17d>;
		#size-cells = <0x01>;
		compatible = "rockchip,rk3399-efuse";
		reg = <0x00 0xff690000 0x00 0x80>;
		phandle = <0xee>;

		cpu-leakage@1a {
			reg = <0x1a 0x01>;
			phandle = <0xf3>;
		};

		center-leakage@19 {
			reg = <0x19 0x01>;
			phandle = <0xf2>;
		};

		logic-leakage@1b {
			reg = <0x1b 0x01>;
			phandle = <0xf4>;
		};

		cpu-id@7 {
			reg = <0x07 0x10>;
			phandle = <0xef>;
		};

		gpu-leakage@18 {
			reg = <0x18 0x01>;
			phandle = <0xf1>;
		};

		wafer-info@1c {
			reg = <0x1c 0x01>;
			phandle = <0xf5>;
		};

		cpu-leakage@17 {
			reg = <0x17 0x01>;
			phandle = <0xf0>;
		};
	};

	qos@ffa70080 {
		compatible = "rockchip,rk3399-qos", "syscon";
		reg = <0x00 0xffa70080 0x00 0x20>;
		phandle = <0x63>;
	};

	interrupt-controller@fee00000 {
		#address-cells = <0x02>;
		interrupts = <0x01 0x09 0x04 0x00>;
		#size-cells = <0x02>;
		compatible = "arm,gic-v3";
		ranges;
		#interrupt-cells = <0x04>;
		reg = <0x00 0xfee00000 0x00 0x10000 0x00 0xfef00000 0x00 0xc0000 0x00 0xfff00000 0x00 0x10000 0x00 0xfff10000 0x00 0x10000 0x00 0xfff20000 0x00 0x10000>;
		phandle = <0x01>;
		interrupt-controller;

		interrupt-controller@fee20000 {
			msi-controller;
			compatible = "arm,gic-v3-its";
			reg = <0x00 0xfee20000 0x00 0x20000>;
			phandle = <0x16>;
			#msi-cells = <0x01>;
		};

		ppi-partitions {

			interrupt-partition-0 {
				affinity = <0x02 0x03 0x04 0x05>;
				phandle = <0x13>;
			};

			interrupt-partition-1 {
				affinity = <0x06 0x07>;
				phandle = <0x14>;
			};
		};
	};

	i2c@ff160000 {
		pinctrl-names = "default";
		#address-cells = <0x01>;
		pinctrl-0 = <0x35>;
		clock-names = "i2c", "pclk";
		assigned-clocks = <0x08 0x46>;
		assigned-clock-rates = <0xbebc200>;
		interrupts = <0x00 0x24 0x04 0x00>;
		clocks = <0x08 0x46 0x08 0x15a>;
		#size-cells = <0x00>;
		compatible = "rockchip,rk3399-i2c";
		status = "disabled";
		reg = <0x00 0xff160000 0x00 0x1000>;
		phandle = <0xc1>;
	};

	qos@ffa98000 {
		compatible = "rockchip,rk3399-qos", "syscon";
		reg = <0x00 0xffa98000 0x00 0x20>;
		phandle = <0x57>;
	};

	display-subsystem {
		ports = <0x0f 0x10>;
		compatible = "rockchip,display-subsystem";
	};

	dp@fec00000 {
		power-domains = <0x18 0x15>;
		clock-names = "core-clk", "pclk", "spdif", "grf";
		assigned-clocks = <0x08 0x72 0x08 0xa1>;
		assigned-clock-rates = <0x5f5e100 0xbebc200>;
		resets = <0x08 0x103 0x08 0x148 0x08 0x14a 0x08 0xfd>;
		interrupts = <0x00 0x09 0x04 0x00>;
		clocks = <0x08 0x72 0x08 0x175 0x08 0xa1 0x08 0x16f>;
		#sound-dai-cells = <0x01>;
		compatible = "rockchip,rk3399-cdn-dp";
		status = "disabled";
		rockchip,grf = <0x19>;
		phys = <0x2c 0x2d>;
		reg = <0x00 0xfec00000 0x00 0x100000>;
		phandle = <0xb7>;
		reset-names = "spdif", "dptx", "apb", "core";

		ports {

			port {
				#address-cells = <0x01>;
				#size-cells = <0x00>;
				phandle = <0xb8>;

				endpoint@1 {
					remote-endpoint = <0x2f>;
					reg = <0x01>;
					phandle = <0x8a>;
				};

				endpoint@0 {
					remote-endpoint = <0x2e>;
					reg = <0x00>;
					phandle = <0x90>;
				};
			};
		};
	};

	typec_power {
		pinctrl-names = "default";
		gpio = <0x22 0x08 0x00>;
		regulator-always-on;
		enable-active-high;
		regulator-name = "typec_power";
		compatible = "regulator-fixed";
		status = "okay";
	};

	rng@ff8b8000 {
		clock-names = "clk_crypto", "hclk_crypto";
		assigned-clocks = <0x08 0x86 0x08 0x1d3>;
		assigned-clock-rates = <0x8f0d180 0x5f5e100>;
		clocks = <0x08 0x86 0x08 0x1d3>;
		compatible = "rockchip,cryptov1-rng";
		status = "okay";
		reg = <0x00 0xff8b8000 0x00 0x1000>;
		phandle = <0x109>;
	};

	iommu@ff670800 {
		clock-names = "aclk", "iface";
		interrupts = <0x00 0x2a 0x04 0x00>;
		clocks = <0x08 0xe1 0x08 0x1dd>;
		#iommu-cells = <0x00>;
		compatible = "rockchip,iommu";
		status = "disabled";
		reg = <0x00 0xff670800 0x00 0x40>;
		phandle = <0xec>;
	};

	spi@ff1e0000 {
		pinctrl-names = "default";
		#address-cells = <0x01>;
		pinctrl-0 = <0x43 0x44 0x45 0x46>;
		clock-names = "spiclk", "apb_pclk";
		interrupts = <0x00 0x34 0x04 0x00>;
		clocks = <0x08 0x49 0x08 0x15d>;
		#size-cells = <0x00>;
		dma-names = "tx", "rx";
		compatible = "rockchip,rk3399-spi", "rockchip,rk3066-spi";
		status = "disabled";
		reg = <0x00 0xff1e0000 0x00 0x1000>;
		phandle = <0xc8>;
		dmas = <0x3a 0x0e 0x3a 0x0f>;
	};

	rga@ff680000 {
		power-domains = <0x18 0x21>;
		clock-names = "aclk", "hclk", "sclk";
		resets = <0x08 0x6a 0x08 0x67 0x08 0x69>;
		interrupts = <0x00 0x37 0x04 0x00>;
		clocks = <0x08 0xdc 0x08 0x1e5 0x08 0x6d>;
		compatible = "rockchip,rk3399-rga";
		reg = <0x00 0xff680000 0x00 0x10000>;
		phandle = <0xed>;
		reset-names = "core", "axi", "ahb";
	};

	i2s@ff890000 {
		power-domains = <0x18 0x1c>;
		pinctrl-names = "default";
		pinctrl-0 = <0x84>;
		clock-names = "i2s_clk", "i2s_hclk";
		interrupts = <0x00 0x28 0x04 0x00>;
		clocks = <0x08 0x57 0x08 0x1d5>;
		dma-names = "tx", "rx";
		#sound-dai-cells = <0x00>;
		compatible = "rockchip,rk3399-i2s", "rockchip,rk3066-i2s";
		status = "disabled";
		reg = <0x00 0xff890000 0x00 0x1000>;
		phandle = <0xfc>;
		dmas = <0x4b 0x02 0x4b 0x03>;
	};

	thermal-zones {
		phandle = <0xcb>;

		cpu-thermal {
			polling-delay = <0x3e8>;
			polling-delay-passive = <0x64>;
			thermal-sensors = <0x50 0x00>;
			phandle = <0xcc>;

			trips {

				cpu_crit {
					temperature = <0x17318>;
					hysteresis = <0x7d0>;
					type = "critical";
					phandle = <0xcd>;
				};

				cpu_alert0 {
					temperature = <0x11170>;
					hysteresis = <0x7d0>;
					type = "passive";
					phandle = <0x51>;
				};

				cpu_alert1 {
					temperature = <0x124f8>;
					hysteresis = <0x7d0>;
					type = "passive";
					phandle = <0x52>;
				};
			};

			cooling-maps {

				map0 {
					trip = <0x51>;
					cooling-device = <0x06 0xffffffff 0xffffffff 0x07 0xffffffff 0xffffffff>;
				};

				map1 {
					trip = <0x52>;
					cooling-device = <0x02 0xffffffff 0xffffffff 0x03 0xffffffff 0xffffffff 0x04 0xffffffff 0xffffffff 0x05 0xffffffff 0xffffffff 0x06 0xffffffff 0xffffffff 0x07 0xffffffff 0xffffffff>;
				};
			};
		};

		gpu-thermal {
			polling-delay = <0x3e8>;
			polling-delay-passive = <0x64>;
			thermal-sensors = <0x50 0x01>;
			phandle = <0xce>;

			trips {

				gpu_alert0 {
					temperature = <0x124f8>;
					hysteresis = <0x7d0>;
					type = "passive";
					phandle = <0x53>;
				};

				gpu_crit {
					temperature = <0x17318>;
					hysteresis = <0x7d0>;
					type = "critical";
					phandle = <0xcf>;
				};
			};

			cooling-maps {

				map0 {
					trip = <0x53>;
					cooling-device = <0x54 0xffffffff 0xffffffff>;
				};
			};
		};
	};

	isp1@ff920000 {
		power-domains = <0x18 0x14>;
		iommus = <0x93>;
		phy-names = "dphy";
		clock-names = "isp", "aclk", "hclk";
		interrupts = <0x00 0x2c 0x04 0x00>;
		clocks = <0x08 0x6f 0x08 0xea 0x08 0x1e4>;
		compatible = "rockchip,rk3399-cif-isp";
		status = "disabled";
		phys = <0x94>;
		reg = <0x00 0xff920000 0x00 0x4000>;
		phandle = <0x100>;

		ports {
			#address-cells = <0x01>;
			#size-cells = <0x00>;

			port@0 {
				#address-cells = <0x01>;
				#size-cells = <0x00>;
				reg = <0x00>;
			};
		};
	};

	video-codec@ff650000 {
		power-domains = <0x18 0x1f>;
		iommus = <0x7d>;
		clock-names = "aclk", "hclk";
		interrupts = <0x00 0x72 0x04 0x00 0x00 0x71 0x04 0x00>;
		clocks = <0x08 0xeb 0x08 0x1ea>;
		compatible = "rockchip,rk3399-vpu";
		interrupt-names = "vepu", "vdpu";
		reg = <0x00 0xff650000 0x00 0x800>;
		phandle = <0xea>;
	};

	pmu_a72 {
		interrupts = <0x01 0x07 0x08 0x14>;
		compatible = "arm,cortex-a72-pmu";
	};

	vcc5v0-sys {
		regulator-max-microvolt = <0x4c4b40>;
		regulator-boot-on;
		regulator-always-on;
		regulator-min-microvolt = <0x4c4b40>;
		regulator-name = "vcc5v0_sys";
		compatible = "regulator-fixed";
		phandle = <0x73>;
	};

	iommu@ff914000 {
		power-domains = <0x18 0x13>;
		clock-names = "aclk", "iface";
		interrupts = <0x00 0x2b 0x04 0x00>;
		clocks = <0x08 0xe9 0x08 0x1e3>;
		#iommu-cells = <0x00>;
		compatible = "rockchip,iommu";
		rockchip,disable-mmu-reset;
		reg = <0x00 0xff914000 0x00 0x100 0x00 0xff915000 0x00 0x100>;
		phandle = <0x91>;
	};

	qos@ffaa0000 {
		compatible = "rockchip,rk3399-qos", "syscon";
		reg = <0x00 0xffaa0000 0x00 0x20>;
		phandle = <0x65>;
	};

	crypto@ff8b0000 {
		clock-names = "hclk_master", "hclk_slave", "sclk";
		resets = <0x08 0xb5 0x08 0xae 0x08 0xaf>;
		interrupts = <0x00 0x00 0x04 0x00>;
		clocks = <0x08 0x1d0 0x08 0x1d2 0x08 0x85>;
		compatible = "rockchip,rk3399-crypto";
		reg = <0x00 0xff8b0000 0x00 0x4000>;
		phandle = <0xba>;
		reset-names = "master", "lave", "crypto";
	};

	psci {
		method = "smc";
		compatible = "arm,psci-1.0";
	};

	xin24m {
		clock-output-names = "xin24m";
		#clock-cells = <0x00>;
		clock-frequency = <0x16e3600>;
		compatible = "fixed-clock";
		phandle = <0x7f>;
	};

	spi@ff200000 {
		power-domains = <0x18 0x1c>;
		pinctrl-names = "default";
		#address-cells = <0x01>;
		pinctrl-0 = <0x4c 0x4d 0x4e 0x4f>;
		clock-names = "spiclk", "apb_pclk";
		interrupts = <0x00 0x84 0x04 0x00>;
		clocks = <0x08 0x4b 0x08 0x15f>;
		#size-cells = <0x00>;
		dma-names = "tx", "rx";
		compatible = "rockchip,rk3399-spi", "rockchip,rk3066-spi";
		status = "disabled";
		reg = <0x00 0xff200000 0x00 0x1000>;
		phandle = <0xca>;
		dmas = <0x4b 0x08 0x4b 0x09>;
	};

	qos@ffae0000 {
		compatible = "rockchip,rk3399-qos", "syscon";
		reg = <0x00 0xffae0000 0x00 0x20>;
		phandle = <0x5d>;
	};

	vdd-log {
		regulator-max-microvolt = <0x155cc0>;
		regulator-boot-on;
		regulator-always-on;
		rockchip,pwm_voltage = <0xdbba0>;
		regulator-min-microvolt = "", "\f5";
		regulator-name = "vdd_log";
		compatible = "pwm-regulator";
		phandle = <0x147>;
		pwms = <0xa7 0x00 0x61a8 0x01>;
	};

	qos@ffab0080 {
		compatible = "rockchip,rk3399-qos", "syscon";
		reg = <0x00 0xffab0080 0x00 0x20>;
		phandle = <0x59>;
	};

	iommu@ff903f00 {
		power-domains = <0x18 0x11>;
		clock-names = "aclk", "iface";
		interrupts = <0x00 0x76 0x04 0x00>;
		clocks = <0x08 0xd9 0x08 0x1d9>;
		#iommu-cells = <0x00>;
		compatible = "rockchip,iommu";
		status = "disabled";
		reg = <0x00 0xff903f00 0x00 0x100>;
		phandle = <0x8b>;
	};

	qos@ffa76000 {
		compatible = "rockchip,rk3399-qos", "syscon";
		reg = <0x00 0xffa76000 0x00 0x20>;
		phandle = <0x61>;
	};

	serial@ff1b0000 {
		reg-io-width = <0x04>;
		pinctrl-names = "default";
		pinctrl-0 = <0x39>;
		clock-names = "baudclk", "apb_pclk";
		interrupts = <0x00 0x65 0x04 0x00>;
		clocks = <0x08 0x54 0x08 0x163>;
		compatible = "rockchip,rk3399-uart", "snps,dw-apb-uart";
		status = "disabled";
		reg = <0x00 0xff1b0000 0x00 0x100>;
		phandle = <0xc5>;
		reg-shift = <0x02>;
	};

	watchdog@ff848000 {
		interrupts = <0x00 0x78 0x04 0x00>;
		clocks = <0x08 0x17c>;
		compatible = "rockchip,rk3399-wdt", "snps,dw-wdt";
		reg = <0x00 0xff848000 0x00 0x100>;
	};

	qos@ffaa8080 {
		compatible = "rockchip,rk3399-qos", "syscon";
		reg = <0x00 0xffaa8080 0x00 0x20>;
		phandle = <0x68>;
	};

	qos@ffa70000 {
		compatible = "rockchip,rk3399-qos", "syscon";
		reg = <0x00 0xffa70000 0x00 0x20>;
		phandle = <0x62>;
	};

	i2c@ff130000 {
		pinctrl-names = "default";
		#address-cells = <0x01>;
		pinctrl-0 = <0x32>;
		clock-names = "i2c", "pclk";
		assigned-clocks = <0x08 0x43>;
		assigned-clock-rates = <0xbebc200>;
		interrupts = <0x00 0x22 0x04 0x00>;
		clocks = <0x08 0x43 0x08 0x157>;
		#size-cells = <0x00>;
		compatible = "rockchip,rk3399-i2c";
		status = "disabled";
		reg = <0x00 0xff130000 0x00 0x1000>;
		phandle = <0xbe>;
	};

	mmc@fe330000 {
		power-domains = <0x18 0x17>;
		mmc-hs400-enhanced-strobe;
		disable-cqe-dcmd;
		clock-output-names = "emmc_cardclock";
		phy-names = "phy_arasan";
		clock-names = "clk_xin", "clk_ahb";
		assigned-clocks = <0x08 0x4e>;
		bus-width = <0x08>;
		non-removable;
		assigned-clock-rates = <0xbebc200>;
		mmc-hs400-1_8v;
		interrupts = <0x00 0x0b 0x04 0x00>;
		clocks = <0x08 0x4e 0x08 0xf0>;
		arasan,soc-ctl-syscon = <0x19>;
		#clock-cells = <0x00>;
		keep-power-in-suspend;
		compatible = "rockchip,rk3399-sdhci-5.1", "arasan,sdhci-5.1";
		status = "okay";
		phys = <0x23>;
		reg = <0x00 0xfe330000 0x00 0x10000>;
		phandle = <0x80>;
		supports-emmc;
	};

	opp-table-2 {
		compatible = "operating-points-v2";
		phandle = <0xa0>;

		opp04 {
			opp-microvolt = <0xe1d48 0xe1d48 0x118c30>;
			opp-hz = <0x00 0x23c34600>;
		};

		opp02 {
			opp-microvolt = <0xc96a8 0xc96a8 0x118c30>;
			opp-hz = <0x00 0x17d78400>;
		};

		opp00 {
			opp-microvolt = <0xc96a8 0xc96a8 0x118c30>;
			opp-hz = <0x00 0xbebc200>;
		};

		opp05 {
			opp-microvolt = <0x10c8e0 0x10c8e0 0x118c30>;
			opp-hz = <0x00 0x2faf0800>;
		};

		opp03 {
			opp-microvolt = <0xd59f8 0xd59f8 0x118c30>;
			opp-hz = <0x00 0x1dcd6500>;
		};

		opp01 {
			opp-microvolt = <0xc96a8 0xc96a8 0x118c30>;
			opp-hz = <0x00 0x11b3dc40>;
		};
	};

	usb_power {
		pinctrl-names = "default";
		gpio = <0xa9 0x1b 0x00>;
		regulator-always-on;
		enable-active-high;
		regulator-name = "typec_power";
		compatible = "regulator-fixed";
		status = "okay";
	};

	tsadc@ff260000 {
		pinctrl-names = "init", "default", "sleep";
		pinctrl-2 = <0x55>;
		pinctrl-0 = <0x55>;
		clock-names = "tsadc", "apb_pclk";
		rockchip,hw-tshut-polarity = <0x01>;
		assigned-clocks = <0x08 0x4f>;
		assigned-clock-rates = <0xb71b0>;
		resets = <0x08 0xe8>;
		interrupts = <0x00 0x61 0x04 0x00>;
		rockchip,hw-tshut-mode = <0x01>;
		clocks = <0x08 0x4f 0x08 0x164>;
		#thermal-sensor-cells = <0x01>;
		compatible = "rockchip,rk3399-tsadc";
		pinctrl-1 = <0x56>;
		status = "okay";
		rockchip,grf = <0x19>;
		reg = <0x00 0xff260000 0x00 0x100>;
		phandle = <0x50>;
		reset-names = "tsadc-apb";
		rockchip,hw-tshut-temp = <0x17318>;
	};

	usb@fe900000 {
		#address-cells = <0x02>;
		clock-names = "ref_clk", "suspend_clk", "bus_clk", "aclk_usb3_rksoc_axi_perf", "aclk_usb3", "grf_clk";
		resets = <0x08 0x126>;
		clocks = <0x08 0x82 0x08 0x84 0x08 0xf7 0x08 0xf8 0x08 0xf4 0x08 0xf9>;
		#size-cells = <0x02>;
		compatible = "rockchip,rk3399-dwc3";
		ranges;
		status = "okay";
		phandle = <0xb5>;
		reset-names = "usb3-otg";

		usb@fe900000 {
			power-domains = <0x18 0x18>;
			snps,dis_enblslpm_quirk;
			phy-names = "usb2-phy", "usb3-phy";
			clock-names = "ref", "bus_early", "suspend";
			snps,dis-u2-freeclk-exists-quirk;
			phy_type = "utmi_wide";
			snps,dis_u2_susphy_quirk;
			interrupts = <0x00 0x6e 0x04 0x00>;
			clocks = <0x08 0x82 0x08 0xf7 0x08 0x84>;
			compatible = "snps,dwc3";
			snps,dis-del-phy-power-chg-quirk;
			status = "okay";
			phys = <0x2a 0x2b>;
			reg = <0x00 0xfe900000 0x00 0x100000>;
			phandle = <0xb6>;
			dr_mode = "host";
			snps,dis-tx-ipgap-linecheck-quirk;
		};
	};

	serial@ff180000 {
		reg-io-width = <0x04>;
		pinctrl-names = "default";
		pinctrl-0 = <0x36>;
		clock-names = "baudclk", "apb_pclk";
		interrupts = <0x00 0x63 0x04 0x00>;
		clocks = <0x08 0x51 0x08 0x160>;
		compatible = "rockchip,rk3399-uart", "snps,dw-apb-uart";
		status = "disabled";
		reg = <0x00 0xff180000 0x00 0x100>;
		phandle = <0xc2>;
		reg-shift = <0x02>;
	};

	usb@fe380000 {
		phy-names = "usb";
		interrupts = <0x00 0x1a 0x04 0x00>;
		clocks = <0x08 0x1c8 0x08 0x1c9 0x24>;
		compatible = "generic-ehci";
		status = "okay";
		phys = <0x25>;
		reg = <0x00 0xfe380000 0x00 0x20000>;
		phandle = <0xaf>;
	};

	ethernet@fe300000 {
		power-domains = <0x18 0x16>;
		pinctrl-names = "default";
		phy-supply = <0x1a>;
		phy-mode = "rgmii";
		snps,txpbl = <0x04>;
		snps,reset-active-low;
		pinctrl-0 = <0x1d>;
		clock-names = "stmmaceth", "mac_clk_rx", "mac_clk_tx", "clk_mac_ref", "clk_mac_refout", "aclk_mac", "pclk_mac";
		assigned-clocks = <0x08 0xa6>;
		assigned-clock-parents = <0x1c>;
		local-mac-address = [f2 92 28 40 10 5f];
		resets = <0x08 0x89>;
		interrupts = <0x00 0x0c 0x04 0x00>;
		clocks = <0x08 0x69 0x08 0x67 0x08 0x68 0x08 0x66 0x08 0x6a 0x08 0xd5 0x08 0x166>;
		mac-address = [f2 92 28 40 10 5f];
		clock_in_out = "input";
		compatible = "rockchip,rk3399-gmac";
		status = "okay";
		rockchip,grf = <0x19>;
		interrupt-names = "macirq";
		snps,reset-gpio = <0x1b 0x0f 0x01>;
		reg = <0x00 0xfe300000 0x00 0x10000>;
		rx_delay = <0x11>;
		phandle = <0xac>;
		reset-names = "stmmaceth";
		tx_delay = <0x28>;
		snps,reset-delays-us = <0x00 0x2710 0xc350>;
	};

	debug@fe434000 {
		clock-names = "apb_pclk";
		clocks = <0x08 0x14d>;
		cpu = <0x04>;
		compatible = "arm,coresight-cpu-debug", "arm,primecell";
		reg = <0x00 0xfe434000 0x00 0x1000>;
	};

	spi@ff350000 {
		pinctrl-names = "default";
		#address-cells = <0x01>;
		pinctrl-0 = <0x6d 0x6e 0x6f 0x70>;
		clock-names = "spiclk", "apb_pclk";
		interrupts = <0x00 0x3c 0x04 0x00>;
		clocks = <0x6c 0x03 0x6c 0x1f>;
		#size-cells = <0x00>;
		compatible = "rockchip,rk3399-spi", "rockchip,rk3066-spi";
		status = "disabled";
		reg = <0x00 0xff350000 0x00 0x1000>;
		phandle = <0xd6>;
	};

	vcc3v3-sys {
		regulator-max-microvolt = <0x325aa0>;
		regulator-boot-on;
		regulator-always-on;
		regulator-min-microvolt = <0x325aa0>;
		regulator-name = "vcc3v3_sys";
		compatible = "regulator-fixed";
		phandle = <0x75>;
	};

	spi@ff1f0000 {
		pinctrl-names = "default";
		#address-cells = <0x01>;
		pinctrl-0 = <0x47 0x48 0x49 0x4a>;
		clock-names = "spiclk", "apb_pclk";
		interrupts = <0x00 0x43 0x04 0x00>;
		clocks = <0x08 0x4a 0x08 0x15e>;
		#size-cells = <0x00>;
		dma-names = "tx", "rx";
		compatible = "rockchip,rk3399-spi", "rockchip,rk3066-spi";
		status = "disabled";
		reg = <0x00 0xff1f0000 0x00 0x1000>;
		phandle = <0xc9>;
		dmas = <0x3a 0x12 0x3a 0x13>;
	};

	syscon@ff320000 {
		compatible = "rockchip,rk3399-pmugrf", "syscon", "simple-mfd";
		reg = <0x00 0xff320000 0x00 0x1000>;
		phandle = <0x11>;

		io-domains {
			compatible = "rockchip,rk3399-pmu-io-voltage-domain";
			status = "disabled";
			phandle = <0xd5>;
		};
	};

	mipi@ff960000 {
		power-domains = <0x18 0x0f>;
		#address-cells = <0x01>;
		clock-names = "ref", "pclk", "phy_cfg", "grf";
		resets = <0x08 0xfb>;
		interrupts = <0x00 0x2d 0x04 0x00>;
		clocks = <0x08 0xa2 0x08 0x170 0x08 0xa3 0x08 0x16f>;
		#size-cells = <0x00>;
		compatible = "rockchip,rk3399-mipi-dsi", "snps,dw-mipi-dsi";
		status = "disabled";
		rockchip,grf = <0x19>;
		reg = <0x00 0xff960000 0x00 0x8000>;
		phandle = <0x104>;
		reset-names = "apb";

		ports {
			#address-cells = <0x01>;
			#size-cells = <0x00>;

			port@0 {
				#address-cells = <0x01>;
				#size-cells = <0x00>;
				reg = <0x00>;
				phandle = <0x105>;

				endpoint@1 {
					remote-endpoint = <0x9a>;
					reg = <0x01>;
					phandle = <0x86>;
				};

				endpoint@0 {
					remote-endpoint = <0x99>;
					reg = <0x00>;
					phandle = <0x8d>;
				};
			};
		};
	};

	iommu@ff8f3f00 {
		power-domains = <0x18 0x12>;
		clock-names = "aclk", "iface";
		interrupts = <0x00 0x77 0x04 0x00>;
		clocks = <0x08 0xdb 0x08 0x1db>;
		#iommu-cells = <0x00>;
		compatible = "rockchip,iommu";
		status = "disabled";
		reg = <0x00 0xff8f3f00 0x00 0x100>;
		phandle = <0x85>;
	};

	timer {
		arm,no-tick-in-suspend;
		interrupts = <0x01 0x0d 0x08 0x00 0x01 0x0e 0x08 0x00 0x01 0x0b 0x08 0x00 0x01 0x0a 0x08 0x00>;
		compatible = "arm,armv8-timer";
	};

	video-codec@ff660000 {
		power-domains = <0x18 0x20>;
		iommus = <0x7e>;
		clock-names = "axi", "ahb", "cabac", "core";
		interrupts = <0x00 0x74 0x04 0x00>;
		clocks = <0x08 0xed 0x08 0x1ec 0x08 0x9f 0x08 0x9e>;
		compatible = "rockchip,rk3399-vdec";
		reg = <0x00 0xff660000 0x00 0x480>;
		phandle = <0xeb>;
	};

	opp-table-0 {
		opp-shared;
		compatible = "operating-points-v2";
		phandle = <0x0b>;

		opp04 {
			opp-microvolt = <0xf4240 0xf4240 0x1312d0>;
			opp-hz = <0x00 0x47868c00>;
		};

		opp02 {
			opp-microvolt = <0xcf850 0xcf850 0x1312d0>;
			opp-hz = <0x00 0x30a32c00>;
		};

		opp00 {
			opp-microvolt = <0xc96a8 0xc96a8 0x1312d0>;
			opp-hz = <0x00 0x18519600>;
			clock-latency-ns = <0x9c40>;
		};

		opp05 {
			opp-microvolt = <0x112a88 0x112a88 0x1312d0>;
			opp-hz = <0x00 0x54667200>;
		};

		opp03 {
			opp-microvolt = <0xe1d48 0xe1d48 0x1312d0>;
			opp-hz = <0x00 0x3c14dc00>;
		};

		opp01 {
			opp-microvolt = <0xc96a8 0xc96a8 0x1312d0>;
			opp-hz = <0x00 0x23c34600>;
		};
	};

	sdio-pwrseq {
		pinctrl-names = "default";
		clock-names = "ext_clock";
		clocks = <0xa8 0x01>;
		reset-gpios = <0x22 0x0a 0x01>;
		compatible = "mmc-pwrseq-simple";
		phandle = <0x1e>;
	};

	iommu@ff924000 {
		power-domains = <0x18 0x14>;
		clock-names = "aclk", "iface";
		interrupts = <0x00 0x2c 0x04 0x00>;
		clocks = <0x08 0xea 0x08 0x1e4>;
		#iommu-cells = <0x00>;
		compatible = "rockchip,iommu";
		rockchip,disable-mmu-reset;
		reg = <0x00 0xff924000 0x00 0x100 0x00 0xff925000 0x00 0x100>;
		phandle = <0x93>;
	};

	vcc-phy {
		pinctrl-names = "default";
		regulator-boot-on;
		gpio = <0x22 0x0c 0x00>;
		regulator-always-on;
		enable-active-high;
		regulator-name = "vcc_phy";
		compatible = "regulator-fixed";
		phandle = <0x1a>;
	};

	i2c@ff3c0000 {
		pinctrl-names = "default";
		#address-cells = <0x01>;
		pinctrl-0 = <0x72>;
		clock-names = "i2c", "pclk";
		assigned-clocks = <0x6c 0x09>;
		i2c-scl-rising-time-ns = <0xa8>;
		i2c-scl-falling-time-ns = <0x04>;
		assigned-clock-rates = <0xbebc200>;
		interrupts = <0x00 0x39 0x04 0x00>;
		clocks = <0x6c 0x09 0x6c 0x1b>;
		#size-cells = <0x00>;
		clock-frequency = <0x61a80>;
		compatible = "rockchip,rk3399-i2c";
		status = "okay";
		reg = <0x00 0xff3c0000 0x00 0x1000>;
		phandle = <0xd8>;

		pmic@1b {
			vcc11-supply = <0x75>;
			pinctrl-names = "default";
			vcc12-supply = <0x75>;
			rockchip,system-power-controller;
			clock-output-names = "xin32k", "rk808-clkout2";
			wakeup-source;
			interrupts = <0x0a 0x08>;
			#clock-cells = <0x01>;
			interrupt-parent = <0x74>;
			vcc1-supply = <0x75>;
			vcc2-supply = <0x75>;
			compatible = "rockchip,rk808";
			vddio-supply = <0x76>;
			vcc3-supply = <0x75>;
			vcc4-supply = <0x75>;
			reg = <0x1b>;
			phandle = <0xa8>;
			vcc6-supply = <0x75>;
			vcc7-supply = <0x75>;
			vcc8-supply = <0x75>;
			vcc9-supply = <0x75>;
			vcc10-supply = <0x75>;

			regulators {

				DCDC_REG4 {
					regulator-max-microvolt = <0x1b7740>;
					regulator-boot-on;
					regulator-always-on;
					regulator-min-microvolt = <0x1b7740>;
					regulator-name = "vcc_1v8";
					phandle = <0xdb>;

					regulator-state-mem {
						regulator-suspend-microvolt = <0x1b7740>;
						regulator-on-in-suspend;
					};
				};

				LDO_REG4 {
					regulator-max-microvolt = <0x325aa0>;
					regulator-boot-on;
					regulator-always-on;
					regulator-min-microvolt = <0x1b7740>;
					regulator-name = "vcc_sdio";
					phandle = <0xde>;

					regulator-state-mem {
						regulator-suspend-microvolt = <0x325aa0>;
						regulator-on-in-suspend;
					};
				};

				DCDC_REG2 {
					regulator-max-microvolt = <0x149970>;
					regulator-boot-on;
					regulator-always-on;
					regulator-min-microvolt = <0xb71b0>;
					regulator-name = "vdd_cpu_l";
					regulator-ramp-delay = <0x1771>;
					phandle = <0x0c>;

					regulator-state-mem {
						regulator-off-in-suspend;
					};
				};

				LDO_REG2 {
					regulator-max-microvolt = <0x2dc6c0>;
					regulator-boot-on;
					regulator-always-on;
					regulator-min-microvolt = <0x2dc6c0>;
					regulator-name = "vcc3v0_tp";
					phandle = <0xdd>;

					regulator-state-mem {
						regulator-off-in-suspend;
					};
				};

				SWITCH_REG1 {
					regulator-boot-on;
					regulator-always-on;
					regulator-name = "vcc3v3_s3";
					phandle = <0xe3>;

					regulator-state-mem {
						regulator-off-in-suspend;
					};
				};

				LDO_REG7 {
					regulator-max-microvolt = <0x1b7740>;
					regulator-boot-on;
					regulator-always-on;
					regulator-min-microvolt = <0x1b7740>;
					regulator-name = "vcc1v8_codec";
					phandle = <0xe1>;

					regulator-state-mem {
						regulator-off-in-suspend;
					};
				};

				LDO_REG5 {
					regulator-max-microvolt = <0x2dc6c0>;
					regulator-boot-on;
					regulator-always-on;
					regulator-min-microvolt = <0x2dc6c0>;
					regulator-name = "vcca3v0_codec";
					phandle = <0xdf>;

					regulator-state-mem {
						regulator-off-in-suspend;
					};
				};

				DCDC_REG3 {
					regulator-boot-on;
					regulator-always-on;
					regulator-name = "vcc_ddr";
					phandle = <0xda>;

					regulator-state-mem {
						regulator-on-in-suspend;
					};
				};

				LDO_REG3 {
					regulator-max-microvolt = <0x1b7740>;
					regulator-boot-on;
					regulator-always-on;
					regulator-min-microvolt = <0x1b7740>;
					regulator-name = "vcc1v8_pmu";
					phandle = <0x76>;

					regulator-state-mem {
						regulator-suspend-microvolt = <0x1b7740>;
						regulator-on-in-suspend;
					};
				};

				DCDC_REG1 {
					regulator-max-microvolt = <0x149970>;
					regulator-boot-on;
					regulator-always-on;
					regulator-min-microvolt = <0xb71b0>;
					regulator-name = "vdd_center";
					regulator-ramp-delay = <0x1771>;
					phandle = <0xd9>;

					regulator-state-mem {
						regulator-off-in-suspend;
					};
				};

				LDO_REG1 {
					regulator-max-microvolt = <0x1b7740>;
					regulator-boot-on;
					regulator-always-on;
					regulator-min-microvolt = <0x1b7740>;
					regulator-name = "vcc1v8_dvp";
					phandle = <0xdc>;

					regulator-state-mem {
						regulator-off-in-suspend;
					};
				};

				SWITCH_REG2 {
					regulator-boot-on;
					regulator-always-on;
					regulator-name = "vcc3v3_s0";
					phandle = <0xe4>;

					regulator-state-mem {
						regulator-off-in-suspend;
					};
				};

				LDO_REG8 {
					regulator-max-microvolt = <0x2dc6c0>;
					regulator-boot-on;
					regulator-always-on;
					regulator-min-microvolt = <0x2dc6c0>;
					regulator-name = "vcc_3v0";
					phandle = <0xe2>;

					regulator-state-mem {
						regulator-suspend-microvolt = <0x2dc6c0>;
						regulator-on-in-suspend;
					};
				};

				LDO_REG6 {
					regulator-max-microvolt = <0x16e360>;
					regulator-boot-on;
					regulator-always-on;
					regulator-min-microvolt = <0x16e360>;
					regulator-name = "vcc_1v5";
					phandle = <0xe0>;

					regulator-state-mem {
						regulator-suspend-microvolt = <0x16e360>;
						regulator-on-in-suspend;
					};
				};
			};
		};

		syr827@40 {
			regulator-max-microvolt = <0x16e360>;
			regulator-boot-on;
			regulator-initial-state = <0x03>;
			regulator-always-on;
			regulator-min-microvolt = <0xadf34>;
			regulator-name = "vdd_cpu_b";
			regulator-ramp-delay = <0x3e8>;
			fcs,suspend-voltage-selector = <0x01>;
			compatible = "silergy,syr827";
			reg = <0x40>;
			phandle = <0x0e>;
			vsel-gpios = <0x74 0x11 0x00>;
			vin-supply = <0x73>;
			regulator-compatible = "fan53555-reg";

			regulator-state-mem {
				regulator-off-in-suspend;
			};
		};

		syr828@41 {
			regulator-max-microvolt = <0x16e360>;
			pinctrl-names = "default";
			regulator-boot-on;
			regulator-initial-state = <0x03>;
			regulator-always-on;
			regulator-min-microvolt = <0xadf34>;
			regulator-name = "vdd_gpu";
			regulator-ramp-delay = <0x3e8>;
			fcs,suspend-voltage-selector = <0x01>;
			compatible = "silergy,syr828";
			reg = <0x41>;
			phandle = <0xa1>;
			vsel-gpios = <0x74 0x0e 0x00>;
			vin-supply = <0x73>;
			regulator-compatible = "fan53555-reg";

			regulator-state-mem {
				regulator-off-in-suspend;
			};
		};
	};

	qos@ffab0000 {
		compatible = "rockchip,rk3399-qos", "syscon";
		reg = <0x00 0xffab0000 0x00 0x20>;
		phandle = <0x58>;
	};

	hdmi@ff940000 {
		power-domains = <0x18 0x15>;
		reg-io-width = <0x04>;
		clock-names = "iahb", "isfr", "cec", "grf", "ref";
		interrupts = <0x00 0x17 0x04 0x00>;
		clocks = <0x08 0x174 0x08 0x71 0x08 0x70 0x08 0x16f 0x08 0x07>;
		#sound-dai-cells = <0x00>;
		compatible = "rockchip,rk3399-dw-hdmi";
		status = "disabled";
		rockchip,grf = <0x19>;
		reg = <0x00 0xff940000 0x00 0x20000>;
		phandle = <0x96>;

		ports {
			#address-cells = <0x01>;
			#size-cells = <0x00>;

			port@0 {
				#address-cells = <0x01>;
				#size-cells = <0x00>;
				reg = <0x00>;
				phandle = <0x102>;

				endpoint@1 {
					remote-endpoint = <0x98>;
					reg = <0x01>;
					phandle = <0x88>;
				};

				endpoint@0 {
					remote-endpoint = <0x97>;
					reg = <0x00>;
					phandle = <0x8e>;
				};
			};

			port@1 {
				reg = <0x01>;
				phandle = <0x103>;
			};
		};
	};

	phy@ff800000 {
		power-domains = <0x18 0x09>;
		clock-names = "tcpdcore", "tcpdphy-ref";
		assigned-clocks = <0x08 0x80>;
		assigned-clock-rates = <0x2faf080>;
		resets = <0x08 0x9d 0x08 0x9c 0x08 0x14d>;
		clocks = <0x08 0x80 0x08 0x7f>;
		compatible = "rockchip,rk3399-typec-phy";
		status = "okay";
		rockchip,grf = <0x19>;
		reg = <0x00 0xff800000 0x00 0x40000>;
		phandle = <0xf8>;
		reset-names = "uphy", "uphy-pipe", "uphy-tcphy";

		dp-port {
			#phy-cells = <0x00>;
			phandle = <0x2d>;
		};

		usb3-port {
			#phy-cells = <0x00>;
			phandle = <0x2b>;
		};
	};

	qos@ffaa8000 {
		compatible = "rockchip,rk3399-qos", "syscon";
		reg = <0x00 0xffaa8000 0x00 0x20>;
		phandle = <0x67>;
	};

	clock-controller@ff750000 {
		#reset-cells = <0x01>;
		clock-names = "xin24m";
		assigned-clocks = <0x6c 0x01>;
		assigned-clock-rates = <0x284af100>;
		clocks = <0x7f>;
		#clock-cells = <0x01>;
		compatible = "rockchip,rk3399-pmucru";
		rockchip,grf = <0x11>;
		reg = <0x00 0xff750000 0x00 0x1000>;
		phandle = <0x6c>;
	};

	crypto@ff8b8000 {
		clock-names = "hclk_master", "hclk_slave", "sclk";
		resets = <0x08 0xba 0x08 0xb8 0x08 0xb9>;
		interrupts = <0x00 0x87 0x04 0x00>;
		clocks = <0x08 0x1d1 0x08 0x1d3 0x08 0x86>;
		compatible = "rockchip,rk3399-crypto";
		reg = <0x00 0xff8b8000 0x00 0x4000>;
		phandle = <0xbb>;
		reset-names = "master", "slave", "crypto";
	};

	aliases {
		i2c3 = "/i2c@ff130000";
		ethernet0 = "/ethernet@fe300000";
		i2c1 = "/i2c@ff110000";
		i2c8 = "/i2c@ff3e0000";
		serial3 = "/serial@ff1b0000";
		i2c6 = "/i2c@ff150000";
		serial1 = "/serial@ff190000";
		i2c4 = "/i2c@ff3d0000";
		i2c2 = "/i2c@ff120000";
		i2c0 = "/i2c@ff3c0000";
		serial4 = "/serial@ff370000";
		mmc0 = "/mmc@fe330000";
		i2c7 = "/i2c@ff160000";
		serial2 = "/serial@ff1a0000";
		i2c5 = "/i2c@ff140000";
		serial0 = "/serial@ff180000";
	};

	qos@ffac0080 {
		compatible = "rockchip,rk3399-qos", "syscon";
		reg = <0x00 0xffac0080 0x00 0x20>;
		phandle = <0x5c>;
	};

	usb@fe800000 {
		#address-cells = <0x02>;
		clock-names = "ref_clk", "suspend_clk", "bus_clk", "aclk_usb3_rksoc_axi_perf", "aclk_usb3", "grf_clk";
		resets = <0x08 0x125>;
		clocks = <0x08 0x81 0x08 0x83 0x08 0xf6 0x08 0xf8 0x08 0xf4 0x08 0xf9>;
		#size-cells = <0x02>;
		compatible = "rockchip,rk3399-dwc3";
		ranges;
		status = "disable";
		phandle = <0xb3>;
		reset-names = "usb3-otg";

		usb@fe800000 {
			power-domains = <0x18 0x18>;
			snps,dis_enblslpm_quirk;
			phy-names = "usb2-phy", "usb3-phy";
			clock-names = "ref", "bus_early", "suspend";
			snps,dis-u2-freeclk-exists-quirk;
			phy_type = "utmi_wide";
			snps,dis_u2_susphy_quirk;
			interrupts = <0x00 0x69 0x04 0x00>;
			clocks = <0x08 0x81 0x08 0xf6 0x08 0x83>;
			compatible = "snps,dwc3";
			snps,dis-del-phy-power-chg-quirk;
			status = "disable";
			phys = <0x28 0x29>;
			reg = <0x00 0xfe800000 0x00 0x100000>;
			phandle = <0xb4>;
			dr_mode = "host";
			snps,dis-tx-ipgap-linecheck-quirk;
		};
	};

	memory-controller {
		clock-names = "dmc_clk";
		clocks = <0x08 0xa8>;
		devfreq-events = <0x12>;
		compatible = "rockchip,rk3399-dmc";
		rockchip,pmu = <0x11>;
		status = "disabled";
		phandle = <0xaa>;
	};

	qos@ffa60180 {
		compatible = "rockchip,rk3399-qos", "syscon";
		reg = <0x00 0xffa60180 0x00 0x20>;
		phandle = <0xd2>;
	};

	usb@fe3c0000 {
		phy-names = "usb";
		interrupts = <0x00 0x1e 0x04 0x00>;
		clocks = <0x08 0x1ca 0x08 0x1cb 0x26>;
		compatible = "generic-ehci";
		status = "okay";
		phys = <0x27>;
		reg = <0x00 0xfe3c0000 0x00 0x20000>;
		phandle = <0xb1>;
	};

	i2s@ff8a0000 {
		power-domains = <0x18 0x1c>;
		clock-names = "i2s_clk", "i2s_hclk";
		interrupts = <0x00 0x29 0x04 0x00>;
		clocks = <0x08 0x58 0x08 0x1d6>;
		dma-names = "tx", "rx";
		#sound-dai-cells = <0x00>;
		compatible = "rockchip,rk3399-i2s", "rockchip,rk3066-i2s";
		status = "disabled";
		reg = <0x00 0xff8a0000 0x00 0x1000>;
		phandle = <0x95>;
		dmas = <0x4b 0x04 0x4b 0x05>;
	};

	edp@ff970000 {
		power-domains = <0x18 0x19>;
		pinctrl-names = "default";
		pinctrl-0 = <0x9d>;
		clock-names = "dp", "pclk", "grf";
		resets = <0x08 0x11d>;
		interrupts = <0x00 0x0a 0x04 0x00>;
		clocks = <0x08 0x16a 0x08 0x16c 0x08 0x16f>;
		compatible = "rockchip,rk3399-edp";
		status = "disabled";
		rockchip,grf = <0x19>;
		reg = <0x00 0xff970000 0x00 0x8000>;
		phandle = <0x107>;
		reset-names = "dp";

		ports {
			#address-cells = <0x01>;
			#size-cells = <0x00>;

			port@0 {
				#address-cells = <0x01>;
				#size-cells = <0x00>;
				reg = <0x00>;
				phandle = <0x108>;

				endpoint@1 {
					remote-endpoint = <0x9f>;
					reg = <0x01>;
					phandle = <0x87>;
				};

				endpoint@0 {
					remote-endpoint = <0x9e>;
					reg = <0x00>;
					phandle = <0x8c>;
				};
			};
		};
	};

	4g_module_power {
		pinctrl-names = "default";
		gpio = <0x74 0x01 0x00>;
		regulator-always-on;
		enable-active-high;
		regulator-name = "4g_module_power";
		compatible = "regulator-fixed";
		status = "okay";
	};

	i2c@ff140000 {
		pinctrl-names = "default";
		#address-cells = <0x01>;
		pinctrl-0 = <0x33>;
		clock-names = "i2c", "pclk";
		assigned-clocks = <0x08 0x44>;
		assigned-clock-rates = <0xbebc200>;
		interrupts = <0x00 0x26 0x04 0x00>;
		clocks = <0x08 0x44 0x08 0x158>;
		#size-cells = <0x00>;
		compatible = "rockchip,rk3399-i2c";
		status = "disabled";
		reg = <0x00 0xff140000 0x00 0x1000>;
		phandle = <0xbf>;
	};

	chosen {
		linux,initrd-end = <0x00 0xf5f279e4>;
		bootargs = "root=UUID=2bf8a87e-f27f-4852-a071-88907b429862 rootwait rootfstype=btrfs splash=verbose console=ttyS2,1500000 console=tty1 consoleblank=0 loglevel=1 ubootpart=582b484f-6550-41bc-ab27-c5ccdac84e8e usb-storage.quirks= rw rootwait net.ifnames=0 max_loop=128 cgroup_enable=cpuset cgroup_memory=1 cgroup_enable=memory swapaccount=1";
		linux,initrd-start = <0x00 0xf5363000>;
	};

	vop@ff900000 {
		power-domains = <0x18 0x11>;
		iommus = <0x8b>;
		clock-names = "aclk_vop", "dclk_vop", "hclk_vop";
		assigned-clocks = <0x08 0xd9 0x08 0x1d9>;
		assigned-clock-rates = <0x17d78400 0x5f5e100>;
		resets = <0x08 0x112 0x08 0x116 0x08 0x118>;
		interrupts = <0x00 0x76 0x04 0x00>;
		clocks = <0x08 0xd9 0x08 0xb4 0x08 0x1d9>;
		compatible = "rockchip,rk3399-vop-big";
		status = "disabled";
		reg = <0x00 0xff900000 0x00 0x2000 0x00 0xff902000 0x00 0x1000>;
		phandle = <0xfe>;
		reset-names = "axi", "ahb", "dclk";

		port {
			#address-cells = <0x01>;
			#size-cells = <0x00>;
			phandle = <0x10>;

			endpoint@3 {
				remote-endpoint = <0x8f>;
				reg = <0x03>;
				phandle = <0x9b>;
			};

			endpoint@1 {
				remote-endpoint = <0x8d>;
				reg = <0x01>;
				phandle = <0x99>;
			};

			endpoint@4 {
				remote-endpoint = <0x90>;
				reg = <0x04>;
				phandle = <0x2e>;
			};

			endpoint@2 {
				remote-endpoint = <0x8e>;
				reg = <0x02>;
				phandle = <0x97>;
			};

			endpoint@0 {
				remote-endpoint = <0x8c>;
				reg = <0x00>;
				phandle = <0x9e>;
			};
		};
	};

	serial@ff190000 {
		reg-io-width = <0x04>;
		pinctrl-names = "default";
		pinctrl-0 = <0x37>;
		clock-names = "baudclk", "apb_pclk";
		interrupts = <0x00 0x62 0x04 0x00>;
		clocks = <0x08 0x52 0x08 0x161>;
		compatible = "rockchip,rk3399-uart", "snps,dw-apb-uart";
		status = "disabled";
		reg = <0x00 0xff190000 0x00 0x100>;
		phandle = <0xc3>;
		reg-shift = <0x02>;
	};

	iommu@ff650800 {
		power-domains = <0x18 0x1f>;
		clock-names = "aclk", "iface";
		interrupts = <0x00 0x73 0x04 0x00>;
		clocks = <0x08 0xeb 0x08 0x1ea>;
		#iommu-cells = <0x00>;
		compatible = "rockchip,iommu";
		reg = <0x00 0xff650800 0x00 0x40>;
		phandle = <0x7d>;
	};

	qos@ffa5c000 {
		compatible = "rockchip,rk3399-qos", "syscon";
		reg = <0x00 0xffa5c000 0x00 0x20>;
		phandle = <0x5f>;
	};

	spi@ff1c0000 {
		pinctrl-names = "default";
		#address-cells = <0x01>;
		pinctrl-0 = <0x3b 0x3c 0x3d 0x3e>;
		clock-names = "spiclk", "apb_pclk";
		interrupts = <0x00 0x44 0x04 0x00>;
		clocks = <0x08 0x47 0x08 0x15b>;
		#size-cells = <0x00>;
		dma-names = "tx", "rx";
		compatible = "rockchip,rk3399-spi", "rockchip,rk3066-spi";
		status = "disabled";
		reg = <0x00 0xff1c0000 0x00 0x1000>;
		phandle = <0xc6>;
		dmas = <0x3a 0x0a 0x3a 0x0b>;
	};

	dma-controller@ff6d0000 {
		clock-names = "apb_pclk";
		interrupts = <0x00 0x05 0x04 0x00 0x00 0x06 0x04 0x00>;
		clocks = <0x08 0xd3>;
		arm,pl330-periph-burst;
		compatible = "arm,pl330", "arm,primecell";
		reg = <0x00 0xff6d0000 0x00 0x4000>;
		phandle = <0x4b>;
		#dma-cells = <0x01>;
	};

	external-gmac-clock {
		clock-output-names = "clkin_gmac";
		#clock-cells = <0x00>;
		clock-frequency = <0x7735940>;
		compatible = "fixed-clock";
		phandle = <0x1c>;
	};

	pmu_a53 {
		interrupts = <0x01 0x07 0x08 0x13>;
		compatible = "arm,cortex-a53-pmu";
	};

	isp0@ff910000 {
		power-domains = <0x18 0x13>;
		iommus = <0x91>;
		phy-names = "dphy";
		clock-names = "isp", "aclk", "hclk";
		interrupts = <0x00 0x2b 0x04 0x00>;
		clocks = <0x08 0x6e 0x08 0xe9 0x08 0x1e3>;
		compatible = "rockchip,rk3399-cif-isp";
		status = "disabled";
		phys = <0x92>;
		reg = <0x00 0xff910000 0x00 0x4000>;
		phandle = <0xff>;

		ports {
			#address-cells = <0x01>;
			#size-cells = <0x00>;

			port@0 {
				#address-cells = <0x01>;
				#size-cells = <0x00>;
				reg = <0x00>;
			};
		};
	};

	debug@fe436000 {
		clock-names = "apb_pclk";
		clocks = <0x08 0x14d>;
		cpu = <0x05>;
		compatible = "arm,coresight-cpu-debug", "arm,primecell";
		reg = <0x00 0xfe436000 0x00 0x1000>;
	};

	mipi@ff968000 {
		power-domains = <0x18 0x0f>;
		#address-cells = <0x01>;
		clock-names = "ref", "pclk", "phy_cfg", "grf";
		resets = <0x08 0xfc>;
		interrupts = <0x00 0x2e 0x04 0x00>;
		clocks = <0x08 0xa2 0x08 0x171 0x08 0xa4 0x08 0x16f>;
		#size-cells = <0x00>;
		#phy-cells = <0x00>;
		compatible = "rockchip,rk3399-mipi-dsi", "snps,dw-mipi-dsi";
		status = "disabled";
		rockchip,grf = <0x19>;
		reg = <0x00 0xff968000 0x00 0x8000>;
		phandle = <0x94>;
		reset-names = "apb";

		ports {
			#address-cells = <0x01>;
			#size-cells = <0x00>;

			port@0 {
				#address-cells = <0x01>;
				#size-cells = <0x00>;
				reg = <0x00>;
				phandle = <0x106>;

				endpoint@1 {
					remote-endpoint = <0x9c>;
					reg = <0x01>;
					phandle = <0x89>;
				};

				endpoint@0 {
					remote-endpoint = <0x9b>;
					reg = <0x00>;
					phandle = <0x8f>;
				};
			};
		};
	};

	cpus {
		#address-cells = <0x02>;
		#size-cells = <0x00>;

		cpu@1 {
			capacity-dmips-mhz = <0x1e5>;
			cpu-supply = <0x0c>;
			clocks = <0x08 0x08>;
			cpu-idle-states = <0x09 0x0a>;
			device_type = "cpu";
			compatible = "arm,cortex-a53";
			dynamic-power-coefficient = <0x64>;
			reg = <0x00 0x01>;
			enable-method = "psci";
			phandle = <0x03>;
			operating-points-v2 = <0x0b>;
			#cooling-cells = <0x02>;
		};

		cpu@101 {
			capacity-dmips-mhz = <0x400>;
			cpu-supply = <0x0e>;
			clocks = <0x08 0x09>;
			cpu-idle-states = <0x09 0x0a>;
			device_type = "cpu";
			compatible = "arm,cortex-a72";
			dynamic-power-coefficient = <0x1b4>;
			reg = <0x00 0x101>;
			enable-method = "psci";
			phandle = <0x07>;
			operating-points-v2 = <0x0d>;
			#cooling-cells = <0x02>;

			thermal-idle {
				exit-latency-us = <0x1f4>;
				duration-us = <0x2710>;
				#cooling-cells = <0x02>;
			};
		};

		idle-states {
			entry-method = "psci";

			cluster-sleep {
				entry-latency-us = <0x190>;
				local-timer-stop;
				exit-latency-us = <0x1f4>;
				arm,psci-suspend-param = <0x1010000>;
				compatible = "arm,idle-state";
				phandle = <0x0a>;
				min-residency-us = <0x7d0>;
			};

			cpu-sleep {
				entry-latency-us = <0x78>;
				local-timer-stop;
				exit-latency-us = <0xfa>;
				arm,psci-suspend-param = <0x10000>;
				compatible = "arm,idle-state";
				phandle = <0x09>;
				min-residency-us = <0x384>;
			};
		};

		cpu-map {

			cluster0 {

				core3 {
					cpu = <0x05>;
				};

				core1 {
					cpu = <0x03>;
				};

				core2 {
					cpu = <0x04>;
				};

				core0 {
					cpu = <0x02>;
				};
			};

			cluster1 {

				core1 {
					cpu = <0x07>;
				};

				core0 {
					cpu = <0x06>;
				};
			};
		};

		cpu@2 {
			capacity-dmips-mhz = <0x1e5>;
			cpu-supply = <0x0c>;
			clocks = <0x08 0x08>;
			cpu-idle-states = <0x09 0x0a>;
			device_type = "cpu";
			compatible = "arm,cortex-a53";
			dynamic-power-coefficient = <0x64>;
			reg = <0x00 0x02>;
			enable-method = "psci";
			phandle = <0x04>;
			operating-points-v2 = <0x0b>;
			#cooling-cells = <0x02>;
		};

		cpu@0 {
			capacity-dmips-mhz = <0x1e5>;
			cpu-supply = <0x0c>;
			clocks = <0x08 0x08>;
			cpu-idle-states = <0x09 0x0a>;
			device_type = "cpu";
			compatible = "arm,cortex-a53";
			dynamic-power-coefficient = <0x64>;
			reg = <0x00 0x00>;
			enable-method = "psci";
			phandle = <0x02>;
			operating-points-v2 = <0x0b>;
			#cooling-cells = <0x02>;
		};

		cpu@100 {
			capacity-dmips-mhz = <0x400>;
			cpu-supply = <0x0e>;
			clocks = <0x08 0x09>;
			cpu-idle-states = <0x09 0x0a>;
			device_type = "cpu";
			compatible = "arm,cortex-a72";
			dynamic-power-coefficient = <0x1b4>;
			reg = <0x00 0x100>;
			enable-method = "psci";
			phandle = <0x06>;
			operating-points-v2 = <0x0d>;
			#cooling-cells = <0x02>;

			thermal-idle {
				exit-latency-us = <0x1f4>;
				duration-us = <0x2710>;
				#cooling-cells = <0x02>;
			};
		};

		cpu@3 {
			capacity-dmips-mhz = <0x1e5>;
			cpu-supply = <0x0c>;
			clocks = <0x08 0x08>;
			cpu-idle-states = <0x09 0x0a>;
			device_type = "cpu";
			compatible = "arm,cortex-a53";
			dynamic-power-coefficient = <0x64>;
			reg = <0x00 0x03>;
			enable-method = "psci";
			phandle = <0x05>;
			operating-points-v2 = <0x0b>;
			#cooling-cells = <0x02>;
		};
	};

	__symbols__ {
		i2s0_2ch_bus = "/pinctrl/i2s0/i2s0-2ch-bus";
		i2c3 = "/i2c@ff130000";
		usb_host1_ohci = "/usb@fe3e0000";
		spi5_clk = "/pinctrl/spi5/spi5-clk";
		vcc3v3_s3 = "/i2c@ff3c0000/pmic@1b/regulators/SWITCH_REG1";
		sdmmc_clk = "/pinctrl/sdmmc/sdmmc-clk";
		vopl_out_mipi = "/vop@ff8f0000/port/endpoint@0";
		tcphy1 = "/phy@ff800000";
		vcc1v8_codec = "/i2c@ff3c0000/pmic@1b/regulators/LDO_REG7";
		cpu_crit = "/thermal-zones/cpu-thermal/trips/cpu_crit";
		thermal_zones = "/thermal-zones";
		qos_gpu = "/qos@ffae0000";
		qos_iep = "/qos@ffa98000";
		clk_32k = "/pinctrl/clock/clk-32k";
		cpu_l1 = "/cpus/cpu@1";
		spi2 = "/spi@ff1e0000";
		pcfg_pull_down_12ma = "/pinctrl/pcfg-pull-down-12ma";
		qos_isp0_m0 = "/qos@ffaa0000";
		gpio0 = "/pinctrl/gpio@ff720000";
		spi4_tx = "/pinctrl/spi4/spi4-tx";
		saradc = "/saradc@ff100000";
		test_clkout1 = "/pinctrl/testclk/test-clkout1";
		vop0_pwm_pin = "/pinctrl/pwm0/vop0-pwm-pin";
		cluster1_opp = "/opp-table-1";
		mipi1_in_vopl = "/mipi@ff968000/ports/port@0/endpoint@1";
		spi0_cs0 = "/pinctrl/spi0/spi0-cs0";
		dfi = "/dfi@ff630000";
		pinctrl = "/pinctrl";
		cif_clkin = "/pinctrl/cif/cif-clkin";
		qos_rga_r = "/qos@ffab0000";
		spi1_tx = "/pinctrl/spi1/spi1-tx";
		dmac_peri = "/dma-controller@ff6e0000";
		vdd_cpu_b = "/i2c@ff3c0000/syr827@40";
		i2s1 = "/i2s@ff890000";
		hdmi_cec = "/pinctrl/hdmi/hdmi-cec";
		i2c1 = "/i2c@ff110000";
		gpu_leakage = "/efuse@ff690000/gpu-leakage@18";
		gmac = "/ethernet@fe300000";
		qos_usb_otg1 = "/qos@ffa70080";
		spi4_cs0 = "/pinctrl/spi4/spi4-cs0";
		pwm3a_pin = "/pinctrl/pwm3a/pwm3a-pin";
		spi4_rx = "/pinctrl/spi4/spi4-rx";
		i2c4_xfer = "/pinctrl/i2c4/i2c4-xfer";
		pcfg_pull_none = "/pinctrl/pcfg-pull-none";
		tcphy1_usb3 = "/phy@ff800000/usb3-port";
		otp_out = "/pinctrl/tsadc/otp-out";
		vopl_out_dp = "/vop@ff8f0000/port/endpoint@4";
		vopl_mmu = "/iommu@ff8f3f00";
		gpu_alert0 = "/thermal-zones/gpu-thermal/trips/gpu_alert0";
		CLUSTER_SLEEP = "/cpus/idle-states/cluster-sleep";
		spi1_rx = "/pinctrl/spi1/spi1-rx";
		sdhci = "/mmc@fe330000";
		sdmmc_bus1 = "/pinctrl/sdmmc/sdmmc-bus1";
		u2phy1 = "/syscon@ff770000/usb2phy@e460";
		gpu = "/gpu@ff9a0000";
		spi0 = "/spi@ff1c0000";
		isp0 = "/isp0@ff910000";
		pwm0_pin = "/pinctrl/pwm0/pwm0-pin";
		clkin_gmac = "/external-gmac-clock";
		usb_host0_ohci = "/usb@fe3a0000";
		dp_in_vopl = "/dp@fec00000/ports/port/endpoint@1";
		sdio0_cmd = "/pinctrl/sdio0/sdio0-cmd";
		dmc = "/memory-controller";
		qos_isp1_m1 = "/qos@ffaa8080";
		qos_emmc = "/qos@ffa58000";
		edp_in = "/edp@ff970000/ports/port@0";
		vcc3v0_tp = "/i2c@ff3c0000/pmic@1b/regulators/LDO_REG2";
		mipi_dphy_rx0 = "/syscon@ff770000/mipi-dphy-rx0";
		uart3_cts = "/pinctrl/uart3/uart3-cts";
		vcc1v8_pmu = "/i2c@ff3c0000/pmic@1b/regulators/LDO_REG3";
		rmii_pins = "/pinctrl/gmac/rmii-pins";
		pmugrf = "/syscon@ff320000";
		sdmmc_wp = "/pinctrl/sdmmc/sdmmc-wp";
		logic_leakage = "/efuse@ff690000/logic-leakage@1b";
		sdio0_bkpwr = "/pinctrl/sdio0/sdio0-bkpwr";
		rktimer = "/rktimer@ff850000";
		vopl = "/vop@ff8f0000";
		qos_pcie = "/qos@ffa60080";
		crypto1 = "/crypto@ff8b8000";
		spi2_clk = "/pinctrl/spi2/spi2-clk";
		i2s0_8ch_bus_bclk_off = "/pinctrl/i2s0/i2s0-8ch-bus-bclk-off";
		gpu_crit = "/thermal-zones/gpu-thermal/trips/gpu_crit";
		vdd_center = "/i2c@ff3c0000/pmic@1b/regulators/DCDC_REG1";
		pcfg_pull_down_18ma = "/pinctrl/pcfg-pull-down-18ma";
		uart4 = "/serial@ff370000";
		uarthdcp_xfer = "/pinctrl/uarthdcp/uarthdcp-xfer";
		u2phy1_host = "/syscon@ff770000/usb2phy@e460/host-port";
		pcie_clkreqnb_cpm = "/pinctrl/pcie/pci-clkreqnb-cpm";
		vdd_gpu = "/i2c@ff3c0000/syr828@41";
		i2c8 = "/i2c@ff3e0000";
		cpu_alert0 = "/thermal-zones/cpu-thermal/trips/cpu_alert0";
		i2c3_xfer = "/pinctrl/i2c3/i2c3-xfer";
		cpu_thermal = "/thermal-zones/cpu-thermal";
		tcphy0_usb3 = "/phy@ff7c0000/usb3-port";
		power = "/power-management@ff310000/power-controller";
		edp_in_vopl = "/edp@ff970000/ports/port@0/endpoint@1";
		mipi_in = "/mipi@ff960000/ports/port@0";
		vopl_out = "/vop@ff8f0000/port";
		pwm3 = "/pwm@ff420030";
		tcphy1_dp = "/phy@ff800000/dp-port";
		vdec_mmu = "/iommu@ff660480";
		sdio0_bus4 = "/pinctrl/sdio0/sdio0-bus4";
		edp_hpd = "/pinctrl/edp/edp-hpd";
		cru = "/clock-controller@ff760000";
		cpu_b1 = "/cpus/cpu@101";
		uart4_xfer = "/pinctrl/uart4/uart4-xfer";
		mipi_dsi1 = "/mipi@ff968000";
		pcfg_pull_down_20ma = "/pinctrl/pcfg-pull-down-20ma";
		uart2 = "/serial@ff1a0000";
		spi1_cs0 = "/pinctrl/spi1/spi1-cs0";
		qos_usb_host0 = "/qos@ffa60100";
		qos_rga_w = "/qos@ffab0080";
		pcfg_output_low = "/pinctrl/pcfg-output-low";
		sdio_pwrseq = "/sdio-pwrseq";
		ppi_cluster0 = "/interrupt-controller@fee00000/ppi-partitions/interrupt-partition-0";
		i2c6 = "/i2c@ff150000";
		vdec = "/video-codec@ff660000";
		sdio0_clk = "/pinctrl/sdio0/sdio0-clk";
		pmu_io_domains = "/syscon@ff320000/io-domains";
		pcfg_pull_none_13ma = "/pinctrl/pcfg-pull-none-13ma";
		spi5_cs0 = "/pinctrl/spi5/spi5-cs0";
		hdmi_i2c_xfer = "/pinctrl/hdmi/hdmi-i2c-xfer";
		gic = "/interrupt-controller@fee00000";
		pcfg_input_pull_down = "/pinctrl/pcfg-input-pull-down";
		hdmi_in_vopb = "/hdmi@ff940000/ports/port@0/endpoint@0";
		pcie0 = "/pcie@f8000000";
		pwm3b_pin = "/pinctrl/pwm3b/pwm3b-pin";
		pcfg_pull_down_8ma = "/pinctrl/pcfg-pull-down-8ma";
		efuse0 = "/efuse@ff690000";
		usbdrd3_1 = "/usb@fe900000";
		pwm1 = "/pwm@ff420010";
		cpu_id = "/efuse@ff690000/cpu-id@7";
		vpu = "/video-codec@ff650000";
		edp = "/edp@ff970000";
		usbdrd_dwc3_0 = "/usb@fe800000/usb@fe800000";
		otp_pin = "/pinctrl/tsadc/otp-pin";
		u2phy0_host = "/syscon@ff770000/usb2phy@e450/host-port";
		i2s0_2ch_bus_bclk_off = "/pinctrl/i2s0/i2s0-2ch-bus-bclk-off";
		spi3_tx = "/pinctrl/spi3/spi3-tx";
		usb_host1_ehci = "/usb@fe3c0000";
		xin24m = "/xin24m";
		pcfg_pull_up_2ma = "/pinctrl/pcfg-pull-up-2ma";
		spi5 = "/spi@ff200000";
		tsadc = "/tsadc@ff260000";
		uart0_cts = "/pinctrl/uart0/uart0-cts";
		gpio3 = "/pinctrl/gpio@ff788000";
		pwm1_pin = "/pinctrl/pwm1/pwm1-pin";
		gpu_opp_table = "/opp-table-2";
		pcfg_output_high = "/pinctrl/pcfg-output-high";
		spi0_tx = "/pinctrl/spi0/spi0-tx";
		uart0 = "/serial@ff180000";
		pwm1_pin_pull_down = "/pinctrl/pwm1/pwm1-pin-pull-down";
		ddrio_pwroff = "/pinctrl/suspend/ddrio-pwroff";
		uart3_rts = "/pinctrl/uart3/uart3-rts";
		i2c2_xfer = "/pinctrl/i2c2/i2c2-xfer";
		pcie_phy = "/syscon@ff770000/pcie-phy";
		rk808 = "/i2c@ff3c0000/pmic@1b";
		u2phy0_otg = "/syscon@ff770000/usb2phy@e450/otg-port";
		qos_hdcp = "/qos@ffa90000";
		i2c4 = "/i2c@ff3d0000";
		cpul_leakage = "/efuse@ff690000/cpu-leakage@1a";
		spi3_rx = "/pinctrl/spi3/spi3-rx";
		vcc_1v5 = "/i2c@ff3c0000/pmic@1b/regulators/LDO_REG6";
		isp0_mmu = "/iommu@ff914000";
		spi0_rx = "/pinctrl/spi0/spi0-rx";
		mipi_in_vopl = "/mipi@ff960000/ports/port@0/endpoint@1";
		iep_mmu = "/iommu@ff670800";
		uart3_xfer = "/pinctrl/uart3/uart3-xfer";
		spdif = "/spdif@ff870000";
		vopl_out_edp = "/vop@ff8f0000/port/endpoint@1";
		spi3_clk = "/pinctrl/spi3/spi3-clk";
		i2c8_xfer = "/pinctrl/i2c8/i2c8-xfer";
		sdmmc_cd = "/pinctrl/sdmmc/sdmmc-cd";
		rng = "/rng@ff8b8000";
		cpu_l2 = "/cpus/cpu@2";
		sdmmc_bus4 = "/pinctrl/sdmmc/sdmmc-bus4";
		sdio0_wp = "/pinctrl/sdio0/sdio0-wp";
		spi3 = "/spi@ff350000";
		qos_isp0_m1 = "/qos@ffaa0080";
		gpio1 = "/pinctrl/gpio@ff730000";
		test_clkout2 = "/pinctrl/testclk/test-clkout2";
		pcfg_pull_up_18ma = "/pinctrl/pcfg-pull-up-18ma";
		vcc5v0_sys = "/vcc5v0-sys";
		qos_vop_big_r = "/qos@ffac8000";
		spi0_cs1 = "/pinctrl/spi0/spi0-cs1";
		its = "/interrupt-controller@fee00000/interrupt-controller@fee20000";
		sdio0 = "/mmc@fe310000";
		hdmi_out = "/hdmi@ff940000/ports/port@1";
		i2s2 = "/i2s@ff8a0000";
		rgmii_pins = "/pinctrl/gmac/rgmii-pins";
		i2c2 = "/i2c@ff120000";
		spdif_bus = "/pinctrl/spdif/spdif-bus";
		vopb_mmu = "/iommu@ff903f00";
		mipi1_in_vopb = "/mipi@ff968000/ports/port@0/endpoint@0";
		usb_host0_ehci = "/usb@fe380000";
		i2s1_2ch_bus = "/pinctrl/i2s1/i2s1-2ch-bus";
		vopb_out_mipi1 = "/vop@ff900000/port/endpoint@3";
		qos_vop_little = "/qos@ffad0000";
		tcphy0 = "/phy@ff7c0000";
		vopl_out_mipi1 = "/vop@ff8f0000/port/endpoint@3";
		pcfg_pull_up_8ma = "/pinctrl/pcfg-pull-up-8ma";
		i2c1_xfer = "/pinctrl/i2c1/i2c1-xfer";
		vcc_3v0 = "/i2c@ff3c0000/pmic@1b/regulators/LDO_REG8";
		cpu_l0 = "/cpus/cpu@0";
		spi2_cs0 = "/pinctrl/spi2/spi2-cs0";
		pmucru = "/clock-controller@ff750000";
		vdd_log = "/vdd-log";
		pcfg_pull_down_4ma = "/pinctrl/pcfg-pull-down-4ma";
		vcc_ddr = "/i2c@ff3c0000/pmic@1b/regulators/DCDC_REG3";
		spi1 = "/spi@ff1d0000";
		vdd_cpu_l = "/i2c@ff3c0000/pmic@1b/regulators/DCDC_REG2";
		pcfg_pull_up_20ma = "/pinctrl/pcfg-pull-up-20ma";
		isp1 = "/isp1@ff920000";
		test_clkout0 = "/pinctrl/testclk/test-clkout0";
		vopb_out_dp = "/vop@ff900000/port/endpoint@4";
		vop1_pwm_pin = "/pinctrl/pwm0/vop1-pwm-pin";
		qos_video_m1_r = "/qos@ffac0000";
		tcphy0_dp = "/phy@ff7c0000/dp-port";
		sdmmc = "/mmc@fe320000";
		i2s0 = "/i2s@ff880000";
		spdif_bus_1 = "/pinctrl/spdif/spdif-bus-1";
		i2c0 = "/i2c@ff3c0000";
		dp_in_vopb = "/dp@fec00000/ports/port/endpoint@0";
		dmac_bus = "/dma-controller@ff6d0000";
		i2c7_xfer = "/pinctrl/i2c7/i2c7-xfer";
		vcc3v3_s0 = "/i2c@ff3c0000/pmic@1b/regulators/SWITCH_REG2";
		uart0_rts = "/pinctrl/uart0/uart0-rts";
		qos_usb_otg0 = "/qos@ffa70000";
		i2s0_8ch_bus = "/pinctrl/i2s0/i2s0-8ch-bus";
		pcfg_pull_none_12ma = "/pinctrl/pcfg-pull-none-12ma";
		uart2c_xfer = "/pinctrl/uart2c/uart2c-xfer";
		vcc_sdio = "/i2c@ff3c0000/pmic@1b/regulators/LDO_REG4";
		io_domains = "/syscon@ff770000/io-domains";
		pwm2_pin = "/pinctrl/pwm2/pwm2-pin";
		vcca3v0_codec = "/i2c@ff3c0000/pmic@1b/regulators/LDO_REG5";
		wafer_info = "/efuse@ff690000/wafer-info@1c";
		pcie0_intc = "/pcie@f8000000/interrupt-controller";
		cif_clkouta = "/pinctrl/cif/cif-clkouta";
		vopb = "/vop@ff900000";
		u2phy0 = "/syscon@ff770000/usb2phy@e450";
		vopb_out_hdmi = "/vop@ff900000/port/endpoint@2";
		u2phy1_otg = "/syscon@ff770000/usb2phy@e460/otg-port";
		vopb_out = "/vop@ff900000/port";
		qos_perihp = "/qos@ffad8080";
		spi0_clk = "/pinctrl/spi0/spi0-clk";
		cpu_alert1 = "/thermal-zones/cpu-thermal/trips/cpu_alert1";
		qos_isp1_m0 = "/qos@ffaa8000";
		spi5_tx = "/pinctrl/spi5/spi5-tx";
		isp1_mmu = "/iommu@ff924000";
		pcfg_input_pull_up = "/pinctrl/pcfg-input-pull-up";
		ap_pwroff = "/pinctrl/suspend/ap-pwroff";
		qos_sdioaudio = "/qos@ffa76000";
		spi2_tx = "/pinctrl/spi2/spi2-tx";
		i2c0_xfer = "/pinctrl/i2c0/i2c0-xfer";
		vcc3v3_sys = "/vcc3v3-sys";
		spi4_clk = "/pinctrl/spi4/spi4-clk";
		edp_in_vopb = "/edp@ff970000/ports/port@0/endpoint@0";
		crypto0 = "/crypto@ff8b0000";
		spi5_rx = "/pinctrl/spi5/spi5-rx";
		pcfg_pull_down = "/pinctrl/pcfg-pull-down";
		pcfg_input_enable = "/pinctrl/pcfg-input-enable";
		pcie_clkreqn_cpm = "/pinctrl/pcie/pci-clkreqn-cpm";
		uart3 = "/serial@ff1b0000";
		pcfg_pull_up = "/pinctrl/pcfg-pull-up";
		qos_vop_big_w = "/qos@ffac8080";
		vpu_mmu = "/iommu@ff650800";
		qos_usb_host1 = "/qos@ffa60180";
		uart1_xfer = "/pinctrl/uart1/uart1-xfer";
		spi2_rx = "/pinctrl/spi2/spi2-rx";
		sdio0_cd = "/pinctrl/sdio0/sdio0-cd";
		cpub_leakage = "/efuse@ff690000/cpu-leakage@17";
		vcc_phy = "/vcc-phy";
		i2c6_xfer = "/pinctrl/i2c6/i2c6-xfer";
		cluster0_opp = "/opp-table-0";
		ppi_cluster1 = "/interrupt-controller@fee00000/ppi-partitions/interrupt-partition-1";
		i2c7 = "/i2c@ff160000";
		vcc_1v8 = "/i2c@ff3c0000/pmic@1b/regulators/DCDC_REG4";
		sdmmc_cmd = "/pinctrl/sdmmc/sdmmc-cmd";
		uart2b_xfer = "/pinctrl/uart2b/uart2b-xfer";
		qos_gmac = "/qos@ffa5c000";
		vopb_out_edp = "/vop@ff900000/port/endpoint@0";
		vopb_out_mipi = "/vop@ff900000/port/endpoint@1";
		pwm2 = "/pwm@ff420020";
		CPU_SLEEP = "/cpus/idle-states/cpu-sleep";
		pcfg_pull_none_18ma = "/pinctrl/pcfg-pull-none-18ma";
		usbdrd_dwc3_1 = "/usb@fe900000/usb@fe900000";
		spi3_cs0 = "/pinctrl/spi3/spi3-cs0";
		qos_video_m0 = "/qos@ffab8000";
		pmu = "/power-management@ff310000";
		pwm2_pin_pull_down = "/pinctrl/pwm2/pwm2-pin-pull-down";
		cpu_b0 = "/cpus/cpu@100";
		gpio4 = "/pinctrl/gpio@ff790000";
		gpu_thermal = "/thermal-zones/gpu-thermal";
		uart1 = "/serial@ff190000";
		hdmi = "/hdmi@ff940000";
		vopl_out_hdmi = "/vop@ff8f0000/port/endpoint@2";
		i2s1_2ch_bus_bclk_off = "/pinctrl/i2s1/i2s1-2ch-bus-bclk-off";
		cdn_dp = "/dp@fec00000";
		qos_video_m1_w = "/qos@ffac0080";
		hdmi_in_vopl = "/hdmi@ff940000/ports/port@0/endpoint@1";
		hdmi_in = "/hdmi@ff940000/ports/port@0";
		i2c5 = "/i2c@ff140000";
		mipi_dsi = "/mipi@ff960000";
		sdio0_pwr = "/pinctrl/sdio0/sdio0-pwr";
		grf = "/syscon@ff770000";
		mipi1_in = "/mipi@ff968000/ports/port@0";
		dp_in = "/dp@fec00000/ports/port";
		usbdrd3_0 = "/usb@fe800000";
		pcfg_pull_none_20ma = "/pinctrl/pcfg-pull-none-20ma";
		pwm0 = "/pwm@ff420000";
		qos_sd = "/qos@ffa74000";
		hdmi_sound = "/hdmi-sound";
		cpu_l3 = "/cpus/cpu@3";
		sdio0_bus1 = "/pinctrl/sdio0/sdio0-bus1";
		uart0_xfer = "/pinctrl/uart0/uart0-xfer";
		sdio0_int = "/pinctrl/sdio0/sdio0-int";
		mipi_in_vopb = "/mipi@ff960000/ports/port@0/endpoint@0";
		spi4 = "/spi@ff1f0000";
		i2c5_xfer = "/pinctrl/i2c5/i2c5-xfer";
		gpio2 = "/pinctrl/gpio@ff780000";
		vcc1v8_dvp = "/i2c@ff3c0000/pmic@1b/regulators/LDO_REG1";
		center_leakage = "/efuse@ff690000/center-leakage@19";
		spi1_clk = "/pinctrl/spi1/spi1-clk";
		rga = "/rga@ff680000";
		uart2a_xfer = "/pinctrl/uart2a/uart2a-xfer";
		pwm0_pin_pull_down = "/pinctrl/pwm0/pwm0-pin-pull-down";
		emmc_phy = "/syscon@ff770000/phy@f780";
	};

	i2c@ff3d0000 {
		pinctrl-names = "default";
		#address-cells = <0x01>;
		pinctrl-0 = <0x77>;
		clock-names = "i2c", "pclk";
		assigned-clocks = <0x6c 0x0a>;
		assigned-clock-rates = <0xbebc200>;
		interrupts = <0x00 0x38 0x04 0x00>;
		clocks = <0x6c 0x0a 0x6c 0x1c>;
		#size-cells = <0x00>;
		compatible = "rockchip,rk3399-i2c";
		status = "disabled";
		reg = <0x00 0xff3d0000 0x00 0x1000>;
		phandle = <0xe5>;
	};

	qos@ffac0000 {
		compatible = "rockchip,rk3399-qos", "syscon";
		reg = <0x00 0xffac0000 0x00 0x20>;
		phandle = <0x5b>;
	};

	debug@fe430000 {
		clock-names = "apb_pclk";
		clocks = <0x08 0x14d>;
		cpu = <0x02>;
		compatible = "arm,coresight-cpu-debug", "arm,primecell";
		reg = <0x00 0xfe430000 0x00 0x1000>;
	};

	qos@ffa60100 {
		compatible = "rockchip,rk3399-qos", "syscon";
		reg = <0x00 0xffa60100 0x00 0x20>;
		phandle = <0xd1>;
	};

	qos@ffab8000 {
		compatible = "rockchip,rk3399-qos", "syscon";
		reg = <0x00 0xffab8000 0x00 0x20>;
		phandle = <0x5a>;
	};

	debug@fe710000 {
		clock-names = "apb_pclk";
		clocks = <0x08 0x14c>;
		cpu = <0x07>;
		compatible = "arm,coresight-cpu-debug", "arm,primecell";
		reg = <0x00 0xfe710000 0x00 0x1000>;
	};

	clock-controller@ff760000 {
		#reset-cells = <0x01>;
		clock-names = "xin24m";
		assigned-clocks = <0x08 0x05 0x08 0x04 0x08 0x06 0x08 0xc0 0x08 0x1c0 0x08 0x140 0x08 0xc2 0x08 0x1c1 0x08 0x142 0x08 0xc9 0x08 0x1c2 0x08 0x143 0x08 0xe3 0x08 0xde 0x08 0x106 0x08 0x178 0x08 0xed>;
		assigned-clock-rates = <0x2367b880 0x2faf0800 0x3b9aca00 0x8f0d180 0x47868c0 0x23c3460 0x5f5e100 0x5f5e100 0x2faf080 0x23c34600 0x5f5e100 0x2faf080 0x17d78400 0x17d78400 0xbebc200 0xbebc200 0x17d78400>;
		clocks = <0x7f>;
		#clock-cells = <0x01>;
		compatible = "rockchip,rk3399-cru";
		rockchip,grf = <0x19>;
		reg = <0x00 0xff760000 0x00 0x1000>;
		phandle = <0x08>;
	};

	vop@ff8f0000 {
		power-domains = <0x18 0x12>;
		iommus = <0x85>;
		clock-names = "aclk_vop", "dclk_vop", "hclk_vop";
		assigned-clocks = <0x08 0xdb 0x08 0x1db>;
		assigned-clock-rates = <0x17d78400 0x5f5e100>;
		resets = <0x08 0x113 0x08 0x117 0x08 0x119>;
		interrupts = <0x00 0x77 0x04 0x00>;
		clocks = <0x08 0xdb 0x08 0xb5 0x08 0x1db>;
		compatible = "rockchip,rk3399-vop-lit";
		status = "disabled";
		reg = <0x00 0xff8f0000 0x00 0x2000 0x00 0xff8f2000 0x00 0x400>;
		phandle = <0xfd>;
		reset-names = "axi", "ahb", "dclk";

		port {
			#address-cells = <0x01>;
			#size-cells = <0x00>;
			phandle = <0x0f>;

			endpoint@3 {
				remote-endpoint = <0x89>;
				reg = <0x03>;
				phandle = <0x9c>;
			};

			endpoint@1 {
				remote-endpoint = <0x87>;
				reg = <0x01>;
				phandle = <0x9f>;
			};

			endpoint@4 {
				remote-endpoint = <0x8a>;
				reg = <0x04>;
				phandle = <0x2f>;
			};

			endpoint@2 {
				remote-endpoint = <0x88>;
				reg = <0x02>;
				phandle = <0x98>;
			};

			endpoint@0 {
				remote-endpoint = <0x86>;
				reg = <0x00>;
				phandle = <0x9a>;
			};
		};
	};

	qos@ffac8080 {
		compatible = "rockchip,rk3399-qos", "syscon";
		reg = <0x00 0xffac8080 0x00 0x20>;
		phandle = <0x6a>;
	};

	serial@ff370000 {
		reg-io-width = <0x04>;
		pinctrl-names = "default";
		pinctrl-0 = <0x71>;
		clock-names = "baudclk", "apb_pclk";
		interrupts = <0x00 0x66 0x04 0x00>;
		clocks = <0x6c 0x06 0x6c 0x22>;
		compatible = "rockchip,rk3399-uart", "snps,dw-apb-uart";
		status = "disabled";
		reg = <0x00 0xff370000 0x00 0x100>;
		phandle = <0xd7>;
		reg-shift = <0x02>;
	};

	spdif@ff870000 {
		power-domains = <0x18 0x1c>;
		pinctrl-names = "default";
		pinctrl-0 = <0x81>;
		clock-names = "mclk", "hclk";
		interrupts = <0x00 0x42 0x04 0x00>;
		clocks = <0x08 0x55 0x08 0x1d7>;
		dma-names = "tx";
		#sound-dai-cells = <0x00>;
		compatible = "rockchip,rk3399-spdif";
		status = "disabled";
		reg = <0x00 0xff870000 0x00 0x1000>;
		phandle = <0xfa>;
		dmas = <0x4b 0x07>;
	};

	i2c@ff110000 {
		pinctrl-names = "default";
		#address-cells = <0x01>;
		pinctrl-0 = <0x30>;
		clock-names = "i2c", "pclk";
		assigned-clocks = <0x08 0x41>;
		assigned-clock-rates = <0xbebc200>;
		interrupts = <0x00 0x3b 0x04 0x00>;
		clocks = <0x08 0x41 0x08 0x155>;
		#size-cells = <0x00>;
		compatible = "rockchip,rk3399-i2c";
		status = "disabled";
		reg = <0x00 0xff110000 0x00 0x1000>;
		phandle = <0xbc>;
	};

	memory {
		device_type = "memory";
		reg = <0x00 0x200000 0x00 0xf7e00000>;
	};

	mmc@fe310000 {
		power-domains = <0x18 0x1c>;
		fifo-depth = <0x100>;
		pinctrl-names = "default";
		#address-cells = <0x01>;
		pinctrl-0 = <0x1f 0x20 0x21>;
		clock-names = "biu", "ciu", "ciu-drive", "ciu-sample";
		cap-sd-highspeed;
		bus-width = <0x04>;
		non-removable;
		resets = <0x08 0x79>;
		cap-sdio-irq;
		interrupts = <0x00 0x40 0x04 0x00>;
		clocks = <0x08 0x1ee 0x08 0x4d 0x08 0x9c 0x08 0x9d>;
		#size-cells = <0x00>;
		keep-power-in-suspend;
		compatible = "rockchip,rk3399-dw-mshc", "rockchip,rk3288-dw-mshc";
		status = "okay";
		mmc-pwrseq = <0x1e>;
		reg = <0x00 0xfe310000 0x00 0x4000>;
		phandle = <0xad>;
		sd-uhs-sdr104;
		max-frequency = <0x8f0d180>;
		reset-names = "reset";

		wifi@1 {
			pinctrl-names = "default";
			interrupts = <0x03 0x00>;
			interrupt-parent = <0x22>;
			brcm,drive-strength = <0x05>;
			compatible = "brcm,bcm4329-fmac";
			interrupt-names = "host-wake";
			reg = <0x01>;
		};
	};

	pwm@ff420030 {
		pinctrl-names = "default";
		pinctrl-0 = <0x7c>;
		clocks = <0x6c 0x1e>;
		#pwm-cells = <0x03>;
		compatible = "rockchip,rk3399-pwm", "rockchip,rk3288-pwm";
		status = "disabled";
		reg = <0x00 0xff420030 0x00 0x10>;
		phandle = <0xe9>;
	};

	qos@ffa90000 {
		compatible = "rockchip,rk3399-qos", "syscon";
		reg = <0x00 0xffa90000 0x00 0x20>;
		phandle = <0x64>;
	};

	qos@ffa60080 {
		compatible = "rockchip,rk3399-qos", "syscon";
		reg = <0x00 0xffa60080 0x00 0x20>;
		phandle = <0xd0>;
	};
};
